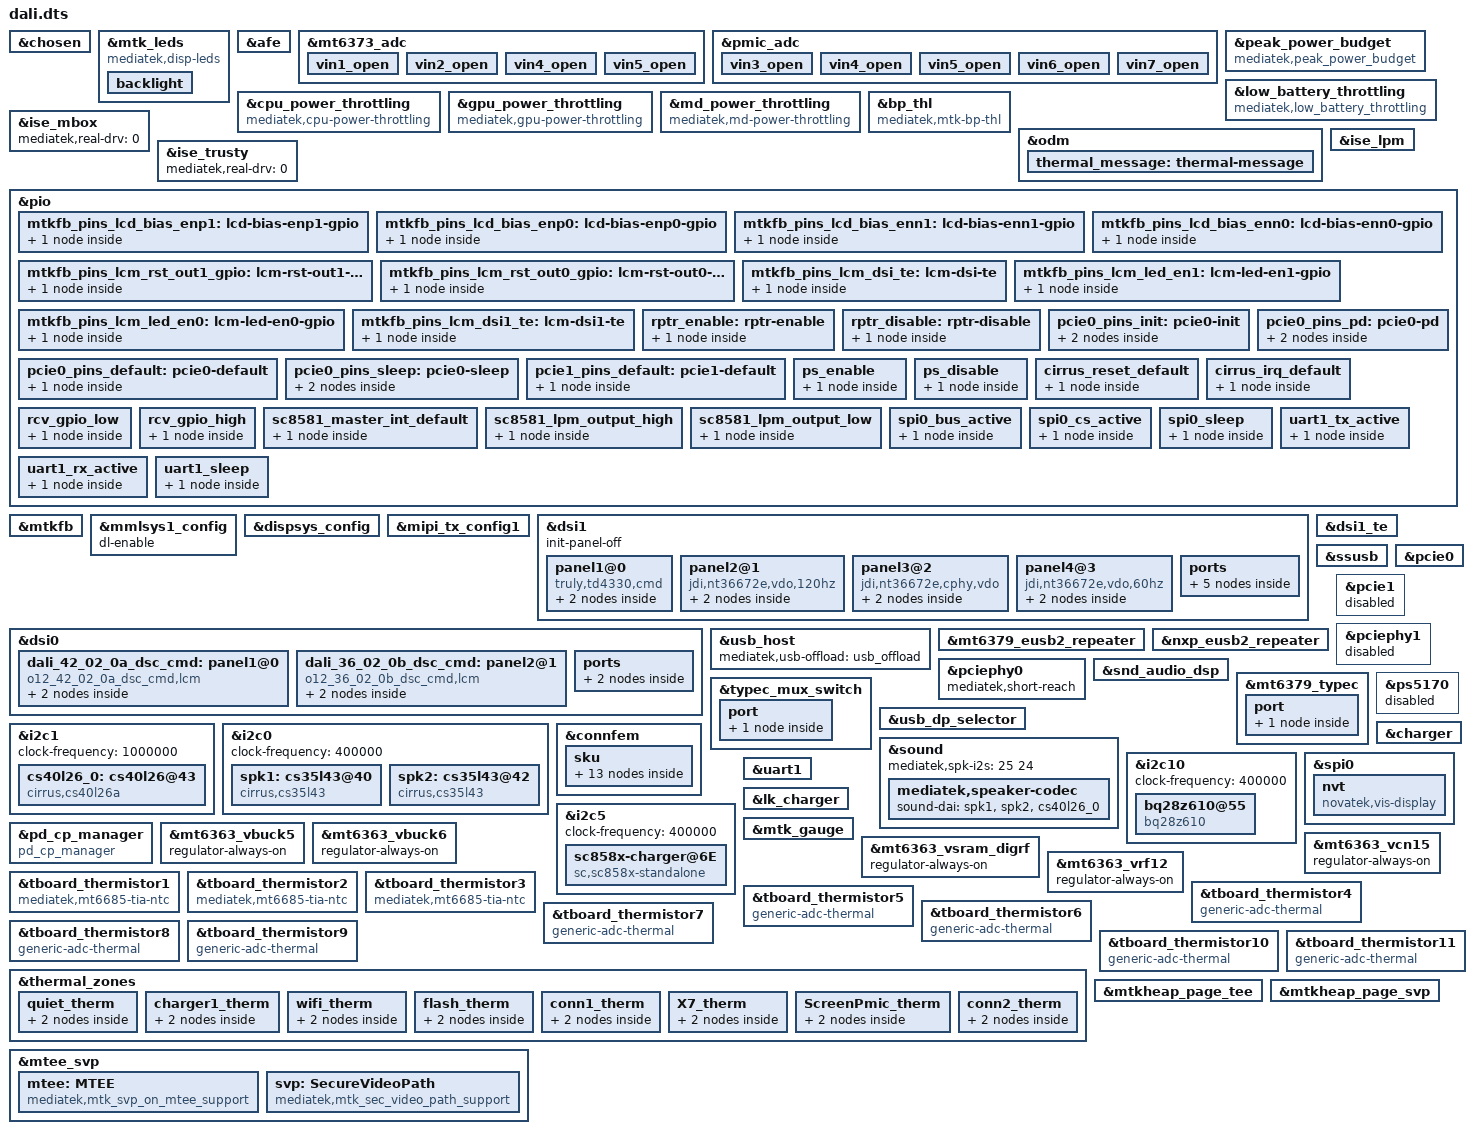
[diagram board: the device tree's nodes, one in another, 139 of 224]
// SPDX-License-Identifier: (GPL-2.0 OR MIT)
/*
 * Copyright (C) 2022 MediaTek Inc.
 */
/dts-v1/;
/plugin/;
#include <dt-bindings/interrupt-controller/arm-gic.h>
#include <dt-bindings/interrupt-controller/irq.h>
#include <dt-bindings/phy/phy.h>
#include <dt-bindings/pinctrl/mt6991-pinfunc.h>
#include <dt-bindings/power/mt6991-power.h>
#include <dt-bindings/gpio/gpio.h>
#include <dt-bindings/input/input.h>
#include <dt-bindings/iio/mt635x-auxadc.h>
#include <dt-bindings/thermal/thermal.h>
#include "mediatek/dali-mt6991-common.dtsi"
#include "mediatek/dali-sensor-common.dtsi"
#include "mediatek/xiaomi_dali_t1_chip.dtsi"


&chosen {
bootargs_ext = "cpufreq.default_governor=conservative \
		rcu_nocbs=0-7";
bootargs_ext_fac = "cpufreq.default_governor=conservative \
		rcu_nocbs=0-7";
};

&mtk_leds {
	compatible = "mediatek,disp-leds";

	backlight {
		max-brightness = <16383>;
		min-brightness = <1>;
		max-hw-brightness = <16383>;
		led_mode = <4>;
		default-state = "FifteenPercent";
	};
};

&afe {
	etdm-out-ch = <2 2 2 2 4 16 2>;
	etdm-in-ch = <2 2 2 2 4 16 16>;
	etdm-in-format = <0 0 0 0 4 0 0>; /*0: I2S; 1: LJ; 2: RJ; 3: EIAJ; 4: DSPA; 5: DSPB; 6: DSD */
	etdm-out-format = <0 0 0 0 4 0 0>;
	etdm-out-sync = <0 0 0 0 0 0 0>; /* 0: disable; 1: enable */
	etdm-in-sync = <1 0 0 0 1 1 1>; /* 0: disable; 1: enable */
	etdm-ip-mode = <0 0 0 0 0 0 0>; /* 0: One IP multi-channel 1: Multi-IP 2-channel */
};

&mt6373_adc {
	vin1_open {
		channel = <AUXADC_VIN1>;
		pures = <ADC_PURES_100K>;
	};
	vin2_open {
		channel = <AUXADC_VIN2>;
		pures = <ADC_PURES_100K>;
	};
	vin4_open {
		channel = <AUXADC_VIN4>;
		pures = <ADC_PURES_100K>;
	};
	vin5_open {
		channel = <AUXADC_VIN5>;
		pures = <ADC_PURES_100K>;
	};
};

&pmic_adc {
	vin3_open {
		channel = <AUXADC_VIN3>;
		pures = <ADC_PURES_100K>;
	};
	vin4_open {
		channel = <AUXADC_VIN4>;
		pures = <ADC_PURES_100K>;
	};
	vin5_open {
		channel = <AUXADC_VIN5>;
		pures = <ADC_PURES_100K>;
	};
	vin6_open {
		channel = <AUXADC_VIN6>;
		pures = <ADC_PURES_100K>;
	};
	vin7_open {
		channel = <AUXADC_VIN7>;
		pures = <ADC_PURES_100K>;
	};
};

&peak_power_budget {
	compatible = "mediatek,peak_power_budget";

	battery-circult-rdc = <15>;
	battery0-path-rac-t0 = <44>;
	battery0-path-rac-t1 = <44>;
	battery0-path-rac-t2 = <44>;
	battery0-path-rac-t3 = <44>;
	battery0-path-rac-t4 = <44>;
	battery0-path-rac-t5 = <44>;
	battery1-path-rac-t0 = <42>;
	battery1-path-rac-t1 = <42>;
	battery1-path-rac-t2 = <42>;
	battery1-path-rac-t3 = <42>;
	battery1-path-rac-t4 = <42>;
	battery1-path-rac-t5 = <42>;

	system-uvlo = <2450>;

	max-temperature-stage = <5>;
	temperature-threshold = <25 10 0 0xFFFFFFF6 0xFFFFFFEC>;

	soc-max-level = <4>;
	soc-hpt-ctrl-lv1 = <7>;
	soc-hpt-ctrl-lv2 = <0>;
	soc-hpt-ctrl-lv3 = <0>;
	soc-hpt-ctrl-lv4 = <0>;

	bat-ocv-table-num = <0>;
};

&low_battery_throttling {
		compatible = "mediatek,low_battery_throttling";
		lvsys-thd-enable = <1>;
		vbat-thd-enable = <1>;
		bat0-thd-volts-l = <
			3100 3000 2850
			3250 3150 3000
			3300 3200 3050
			3450 3350 3200
			3570 3470 3320>;
		bat0-thd-volts-h = <
			3200 3100 3000
			3350 3250 3150
			3400 3300 3200
			3550 3450 3350
			3670 3570 3470>;
		bat1-thd-volts-l = <
			3170 3070 2920
			3230 3130 2980
			3290 3190 3040
			3400 3300 3150
			3746 3646 3496>;
		bat1-thd-volts-h = <
			3270 3170 3070
			3330 3230 3130
			3390 3290 3190
			3500 3400 3300
			3846 3746 3646>;
		lvsys-thd-volt-l = <2850>;
		lvsys-thd-volt-h = <3000>;
		temperature-stage-threshold = <25 10 0 0xFFFFFFF6>;

		throttle-level = <0 1 2 3>,
				<0 1 2 3>,
				<0 1 2 3>,
				<0 1 2 3>,
				<0 1 2 3>;
};

&cpu_power_throttling{
	compatible = "mediatek,cpu-power-throttling";

	lbat-max-level = <3>;
	lbat-limit-freq-lv1 = < 1200000  1200000 1200000>;
	lbat-limit-freq-lv2 = < 1200000  1200000 1200000>;
	lbat-limit-freq-lv3 = < 330000  550000 670000>;

	oc-max-level = <2>;
	oc-limit-freq-lv1 = < 2147483647  2147483647 2147483647>;
	oc-limit-freq-lv2 = < 1200000  1700000 1900000>;

	soc-max-level = <4>;
	soc-core-active-lv1 = < 1 1 1 1 1 1 1 1 >;
	soc-core-active-lv2 = < 1 1 1 1 1 1 1 1 >;
	soc-core-active-lv3 = < 1 1 1 1 1 1 1 1 >;
	soc-core-active-lv4 = < 1 1 1 1 1 1 0 0 >;
	soc-limit-freq-lv1 = < 2147483647  2147483647 2147483647 >;
	soc-limit-freq-lv2 = < 2147483647  2147483647 2147483647 >;
	soc-limit-freq-lv3 = < 1200000 1200000 1200000>;
	soc-limit-freq-lv4 = < 1800000 900000 670000>;
};

&gpu_power_throttling{
	compatible = "mediatek,gpu-power-throttling";

	lbat-max-level = <3>;
	lbat-limit-freq-lv1 = <754000>;
	lbat-limit-freq-lv2 = <754000>;
	lbat-limit-freq-lv3 = <338000>;

	oc-max-level = <2>;
	oc-limit-freq-lv1 = <988000>;
	oc-limit-freq-lv2 = <572000>;

	soc-max-level = <4>;
	soc-limit-freq-lv1 = <2147483647>;
	soc-limit-freq-lv2 = <2147483647>;
	soc-limit-freq-lv3 = <754000>;
	soc-limit-freq-lv4 = <338000>;
};

&md_power_throttling {
		compatible = "mediatek,md-power-throttling";
		lbat-dedicate-volts = <3700 3400 3200 3000>;

		lbat-max-level = <3>;
		lbat-reduce-tx-lv1 = <0>;
		lbat-reduce-tx-lv2 = <2>;
		lbat-reduce-tx-lv3 = <2>;

		oc-max-level = <2>;
		oc-reduce-tx-lv1 = <0>;
		oc-reduce-tx-lv2 = <6>;

		soc-max-level = <0>;
};

&bp_thl{
	compatible = "mediatek,mtk-bp-thl";

	max-throttle-level = <4>;
	soc-throttle-level = <0 1 1 2 3>, //temperature stage 0
					<0 1 1 2 3>, //temperature stage 1
					<0 1 1 2 3>, //temperature stage 2
					<0 1 4 4 4>; //temperature stage 3

	soc-max-stage = <4>;
	soc-limit-threshold = <15 7 6 5>;

	temperature-max-stage = <3>;
	temperature-stage-threshold = <25 10 0>;

	md-soc-throttle-l = <20>;
	md-soc-throttle-h = <25>;
};

&odm {
	thermal_message: thermal-message {
		board-sensor = "VIRTUAL-SENSOR";
		board-sensor-trip-enable = <1>;
		trip-point-high = <41000>;
		trip-point-low = <40000>;
	};
};

&ise_mbox {
	mediatek,real-drv = <0>;
};

&ise_lpm {
	ise-wakelock = <0>;
	ise-lpm-freerun = <0>;
	ise-lpm-deinit-bypass = <0>;
};

&ise_trusty {
	mediatek,real-drv = <0>;
};



&pio {
	mtkfb_pins_lcd_bias_enp1: lcd-bias-enp1-gpio {
		pins-cmd-dat {
			pinmux = <PINMUX_GPIO103__FUNC_GPIO103>;
			slew-rate = <1>;
			output-high;
		};
	};

	mtkfb_pins_lcd_bias_enp0: lcd-bias-enp0-gpio {
		pins-cmd-dat {
			pinmux = <PINMUX_GPIO103__FUNC_GPIO103>;
			slew-rate = <1>;
			output-low;
		};
	};

	mtkfb_pins_lcd_bias_enn1: lcd-bias-enn1-gpio {
		pins-cmd-dat {
			pinmux = <PINMUX_GPIO103__FUNC_GPIO103>;
			slew-rate = <1>;
			output-high;
		};
	};

	mtkfb_pins_lcd_bias_enn0: lcd-bias-enn0-gpio {
		pins-cmd-dat {
			pinmux = <PINMUX_GPIO103__FUNC_GPIO103>;
			slew-rate = <1>;
			output-low;
		};
	};

	mtkfb_pins_lcm_rst_out1_gpio: lcm-rst-out1-gpio {
		pins-cmd-dat {
			pinmux = <PINMUX_GPIO90__FUNC_GPIO90>;
			slew-rate = <1>;
			output-high;
		};
	};

	mtkfb_pins_lcm_rst_out0_gpio: lcm-rst-out0-gpio {
		pins-cmd-dat {
			pinmux = <PINMUX_GPIO90__FUNC_GPIO90>;
			slew-rate = <1>;
			output-low;
		};
	};

	mtkfb_pins_lcm_dsi_te: lcm-dsi-te {
		pins-cmd-dat {
			pinmux = <PINMUX_GPIO89__FUNC_DSI_TE>;
		};
	};

	mtkfb_pins_lcm_led_en1: lcm-led-en1-gpio {
		pins-cmd-dat {
			pinmux = <PINMUX_GPIO174__FUNC_GPIO174>;
			slew-rate = <1>;
			output-high;
		};
	};

	mtkfb_pins_lcm_led_en0: lcm-led-en0-gpio {
		pins-cmd-dat {
			pinmux = <PINMUX_GPIO174__FUNC_GPIO174>;
			slew-rate = <1>;
			output-low;
		};
	};

	mtkfb_pins_lcm_dsi1_te: lcm-dsi1-te {
		pins-cmd-dat {
			pinmux = <PINMUX_GPIO6__FUNC_DSI1_TE>;
		};
	};
};

&mtkfb {
	pinctrl-names = "lcd_bias_enp1_gpio", "lcd_bias_enp0_gpio",
		"lcd_bias_enn1_gpio", "lcd_bias_enn0_gpio",
		"lcm_rst_out1_gpio", "lcm_rst_out0_gpio",
		"mode_te_te", "lcm_led_en1_gpio", "lcm_led_en0_gpio",
		"mode_te_te1";
	pinctrl-0 = <&mtkfb_pins_lcd_bias_enp1>;
	pinctrl-1 = <&mtkfb_pins_lcd_bias_enp0>;
	pinctrl-2 = <&mtkfb_pins_lcd_bias_enn1>;
	pinctrl-3 = <&mtkfb_pins_lcd_bias_enn0>;
	pinctrl-4 = <&mtkfb_pins_lcm_rst_out1_gpio>;
	pinctrl-5 = <&mtkfb_pins_lcm_rst_out0_gpio>;
	pinctrl-6 = <&mtkfb_pins_lcm_dsi_te>;
	pinctrl-7 = <&mtkfb_pins_lcm_led_en1>;
	pinctrl-8 = <&mtkfb_pins_lcm_led_en0>;
	pinctrl-9 = <&mtkfb_pins_lcm_dsi1_te>;

	status = "okay";
};

&mmlsys1_config {
	 dl-enable;
};

&dispsys_config {
	pinctrl-names = "mode_te_te", "mode_te_te1";
	pinctrl-0 = <&mtkfb_pins_lcm_dsi_te>;
	pinctrl-1 = <&mtkfb_pins_lcm_dsi1_te>;

	status = "okay";
	lk_mode_index = <2>;
//	enable-discrete-path = <1>;

	helper-value = <0>, /*MTK_DRM_OPT_STAGE*/
		<1>, /*MTK_DRM_OPT_USE_CMDQ*/
		<1>, /*MTK_DRM_OPT_USE_M4U*/
		<1>, /*MTK_DRM_OPT_MMQOS_SUPPORT*/
		<1>, /*MTK_DRM_OPT_MMDVFS_SUPPORT*/
		<0>, /*MTK_DRM_OPT_SODI_SUPPORT*/
		<1>, /*MTK_DRM_OPT_IDLE_MGR*/
		<0>, /*MTK_DRM_OPT_IDLEMGR_SWTCH_DECOUPLE*/
		<0>, /*MTK_DRM_OPT_IDLEMGR_BY_REPAINT*/
		<0>, /*MTK_DRM_OPT_IDLEMGR_ENTER_ULPS*/
		<0>, /*MTK_DRM_OPT_IDLEMGR_KEEP_LP11*/
		<0>, /*MTK_DRM_OPT_DYNAMIC_RDMA_GOLDEN_SETTING*/
		<1>, /*MTK_DRM_OPT_IDLEMGR_DISABLE_ROUTINE_IRQ*/
		<1>, /*MTK_DRM_OPT_IDLEMGR_ASYNC*/
		<0>, /*MTK_DRM_OPT_MET_LOG*/
		<1>, /*MTK_DRM_OPT_USE_PQ*/
		<1>, /*MTK_DRM_OPT_ESD_CHECK_RECOVERY*/
		<1>, /*MTK_DRM_OPT_ESD_CHECK_SWITCH*/
		<1>, /*MTK_DRM_OPT_PRESENT_FENCE*/
		<0>, /*MTK_DRM_OPT_RDMA_UNDERFLOW_AEE*/
		<1>, /*MTK_DRM_OPT_DSI_UNDERRUN_AEE*/
		<0>, /*MTK_DRM_OPT_ODDMR_UNDERRUN_AEE*/
		<1>, /*MTK_DRM_OPT_HRT*/
		<0>, /*MTK_DRM_OPT_HRT_MODE*/
		<0>, /*MTK_DRM_OPT_DELAYED_TRIGGER*/
		<0>, /*MTK_DRM_OPT_OVL_EXT_LAYER*/
		<0>, /*MTK_DRM_OPT_AOD*/
		<1>, /*MTK_DRM_OPT_RPO*/
		<0>, /*MTK_DRM_OPT_DUAL_PIPE*/
		<0>, /*MTK_DRM_OPT_DC_BY_HRT*/
		<1>, /*MTK_DRM_OPT_OVL_WCG*/
		<0>, /*MTK_DRM_OPT_OVL_SBCH*/
		<1>, /*MTK_DRM_OPT_COMMIT_NO_WAIT_VBLANK*/
		<0>, /*MTK_DRM_OPT_MET*/
		<0>, /*MTK_DRM_OPT_REG_PARSER_RAW_DUMP*/
		<0>, /*MTK_DRM_OPT_VP_PQ*/
		<0>, /*MTK_DRM_OPT_GAME_PQ*/
		<0>, /*MTK_DRM_OPT_MMPATH*/
		<0>, /*MTK_DRM_OPT_HBM*/
		<0>, /*MTK_DRM_OPT_VDS_PATH_SWITCH*/
		<0>, /*MTK_DRM_OPT_LAYER_REC*/
		<1>, /*MTK_DRM_OPT_CLEAR_LAYER*/
		<0>, /*MTK_DRM_OPT_LFR*/
		<0>, /*MTK_DRM_OPT_SF_PF*/
		<0>, /*MTK_DRM_OPT_DYN_MIPI_CHANGE*/
		<0>, /*MTK_DRM_OPT_PRIM_DUAL_PIPE*/
		<0>, /*MTK_DRM_OPT_MSYNC2_0*/
		<0>, /*MTK_DRM_OPT_MSYNC2_0_WAIT_EPT*/
		<1>, /*MTK_DRM_OPT_MML_PRIMARY*/
		<1>, /*MTK_DRM_OPT_MML_SUPPORT_CMD_MODE*/
		<1>, /*MTK_DRM_OPT_MML_PQ*/
		<1>, /*MTK_DRM_OPT_MML_IR*/
		<0>, /*MTK_DRM_OPT_DUAL_TE*/
		<0>, /*MTK_DRM_OPT_RES_SWITCH*/
		<0>, /*MTK_DRM_OPT_RES_SWITCH_ON_AP*/
		<0>, /*MTK_DRM_OPT_PREFETCH_TE*/
		<0>, /*MTK_DRM_OPT_VIDLE_APSRC_OFF*/
		<0>, /*MTK_DRM_OPT_VIDLE_DSI_PLL_OFF*/
		<0>, /*MTK_DRM_OPT_CHECK_TRIGGER_MERGE*/
		<0>, /*MTK_DRM_OPT_VIRTUAL_DISP*/
		<1>, /*MTK_DRM_OPT_OVL_BW_MONITOR*/
		<0>, /*MTK_DRM_OPT_GPU_CACHE*/
		<1>, /*MTK_DRM_OPT_SPHRT*/
		<0>, /*MTK_DRM_OPT_SDPA_OVL_SWITCH*/
		<1>, /*MTK_DRM_OPT_HRT_BY_LARB*/
		<0>, /*MTK_DRM_OPT_TILE_OVERHEAD*/
		<1>, /*MTK_DRM_OPT_VIDLE_TOP_EN*/
		<0>, /*MTK_DRM_OPT_VIDLE_MTCMOS_DT_EN*/
		<0>, /*MTK_DRM_OPT_VIDLE_MMINFRA_DT_EN*/
		<0>, /*MTK_DRM_OPT_VIDLE_DVFS_DT_EN*/
		<0>, /*MTK_DRM_OPT_VIDLE_QOS_DT_EN*/
		<0>, /*MTK_DRM_OPT_VIDLE_GCE_TS_EN*/
		<1>, /*MTK_DRM_OPT_VIDLE_FULL_SCENARIO*/
		<0>, /*MTK_DRM_OPT_DPC_PRE_TE_EN*/
		<1>, /*MTK_DRM_OPT_PARTIAL_UPDATE*/
		<0>, /*MTK_DRM_OPT_SLC_ALL_CACHE*/
		<1>, /*MTK_DRM_OPT_OVL_WCG_BY_COLOR_MODE*/
		<0>, /*"MTK_DRM_OPT_OVLSYS_CASCADE"*/
		<1>; /*MTK_DRM_OPT_LTPO_VM*/
};

&mipi_tx_config1 {
//	status = "okay";
};

&dsi1 {
//	status = "okay";
	#address-cells = <1>;
	#size-cells = <0>;
	init-panel-off;
	panel1@0 {
		compatible = "truly,td4330,cmd";
		reg = <0>;
		pm-enable-gpios = <&pio 215 0>;
		reset-gpios = <&pio 5 0>;
		swap-from-dts;
		lane-swap-setting = <1 2 0 3 4 2>;
		pn-swap-setting = <1 1 1 1 1 1>;
		gate-ic = <4831>;
		pinctrl-names = "default";
		port {
			panel1_in: endpoint {
				remote-endpoint = <&dsi1_out>;
			};
		};
	};
	panel2@1 {
		compatible = "jdi,nt36672e,vdo,120hz";
		reg = <1>;
		pm-enable-gpios = <&pio 215 0>;
		reset-gpios = <&pio 5 0>;
		gate-ic = <4831>;
		pinctrl-names = "default";
		port {
			panel2_in: endpoint {
				remote-endpoint = <&dsi1_out2>;
			};
		};
	};
	panel3@2 {
		compatible = "jdi,nt36672e,cphy,vdo";
		reg = <2>;
		pm-enable-gpios = <&pio 215 0>;
		reset-gpios = <&pio 5 0>;
		gate-ic = <4831>;
		pinctrl-names = "default";
		port {
			panel3_in: endpoint {
				remote-endpoint = <&dsi1_out3>;
			};
		};
	};
	panel4@3 {
		compatible = "jdi,nt36672e,vdo,60hz";
		reg = <3>;
		pm-enable-gpios = <&pio 215 0>;
		reset-gpios = <&pio 5 0>;
		gate-ic = <4831>;
		pinctrl-names = "default";
		port {
			panel4_in: endpoint {
				remote-endpoint = <&dsi1_out4>;
			};
		};
	};
	ports {
		port {
			dsi1_out: endpoint@0 {
				remote-endpoint = <&panel1_in>;
			};

			dsi1_out2: endpoint@1 {
				remote-endpoint = <&panel2_in>;
			};

			dsi1_out3: endpoint@2 {
				remote-endpoint = <&panel3_in>;
			};

			dsi1_out4: endpoint@3 {
				remote-endpoint = <&panel4_in>;
			};
		};
	};
};

&dsi1_te {
	interrupt-parent = <&pio>;
	interrupts = <6 1 6 1>;
	status = "okay";
};

&dsi0 {
	status = "okay";
	#address-cells = <1>;
	#size-cells = <0>;

	dali_42_02_0a_dsc_cmd: panel1@0 {
		compatible = "o12_42_02_0a_dsc_cmd,lcm";
		reg = <0>;
		reset-gpios = <&pio 90 0>;
		mi,esd-err-irq-gpio = <&pio 6 0x2002>;
		lane-swap-setting = <1 2 0 3 4 2>;
		pn-swap-setting = <1 1 1 1 1 1>;
		pinctrl-names = "default";
		vcn18io-supply = <&mt6373_vcn18io>;
		vibr-supply = <&mt6373_vibr>;
		//vbuck8-supply = <&mt6373_vbuck8>;
		dvdd-gpios = <&pio 92 0>;
		nt335_0p8-gpios = <&pio 26 0>;
		nt335_1p8-gpios = <&pio 181 0>;
		nt335_xtal1p8-gpios = <&pio 206 0>;
		port {
			panel_in1: endpoint {
				remote-endpoint = <&dsi_out>;
			};
		};
	};
	dali_36_02_0b_dsc_cmd: panel2@1 {
		compatible = "o12_36_02_0b_dsc_cmd,lcm";
		reg = <1>;
		reset-gpios = <&pio 90 0>;
		mi,esd-err-irq-gpio = <&pio 6 0x2002>;
		lane-swap-setting = <1 2 0 3 4 2>;
		pn-swap-setting = <1 1 1 1 1 1>;
		pinctrl-names = "default";
		vcn18io-supply = <&mt6373_vcn18io>;
		vibr-supply = <&mt6373_vibr>;
		//vbuck8-supply = <&mt6373_vbuck8>;
		dvdd-gpios = <&pio 92 0>;
		nt335_0p8-gpios = <&pio 26 0>;
		nt335_1p8-gpios = <&pio 181 0>;
		nt335_xtal1p8-gpios = <&pio 206 0>;
		port {
			panel_in2: endpoint {
				remote-endpoint = <&dsi_out>;
			};
		};
	};
	ports {
		port {
			dsi_out: endpoint {
				remote-endpoint = <&panel_in1>;
			};
		};
	};
};

&pio {
	rptr_enable: rptr-enable {
		pins-cmd-dat {
			pinmux = <PINMUX_GPIO72__FUNC_GPIO72>;
			output-high;
		};
	};

	rptr_disable: rptr-disable {
		pins-cmd-dat {
			pinmux = <PINMUX_GPIO72__FUNC_GPIO72>;
			output-low;
		};
	};
};

&ssusb {
	mediatek,force-vbus;
	mediatek,clk-mgr;
	mediatek,usb3-drd;
	mediatek,uds = <&usb_dp_selector 19>;
	mediatek,eusb2-cm-l1 = <0x474>;
	usb-role-switch;
	status = "okay";
};

&usb_host {
	mediatek,usb-offload = <&usb_offload>;
	status = "okay";
};

&mt6379_eusb2_repeater {
	mediatek,discth = <0xf>;
	mediatek,equalization = <0x4>;
	mediatek,intr-ofs = "2";
	mediatek,pre-emphasis = <0x5>;
	mediatek,rx-sqth = <0x0>;
	mediatek,term-ofs = "4";
	mediatek,vrt-sel = <0x2>;

	mediatek,host-discth = <0xd>;
	mediatek,host-equalization = <0x4>;
	mediatek,host-intr-ofs = "3";
	mediatek,host-pre-emphasis = <0x2>;
	mediatek,host-rx-sqth = <0x0>;
	mediatek,host-term-ofs = "-2";
	mediatek,host-vrt-sel = <0x2>;
	status = "okay";
};

&nxp_eusb2_repeater {
	pinctrl-names = "enable", "disable";
	pinctrl-0 = <&rptr_enable>;
	pinctrl-1 = <&rptr_disable>;
	status = "okay";
};

&pcie0 {
	pinctrl-names = "init", "default", "sleep", "pd";
	pinctrl-0 = <&pcie0_pins_init>;
	pinctrl-1 = <&pcie0_pins_default>;
	pinctrl-2 = <&pcie0_pins_sleep>;
	pinctrl-3 = <&pcie0_pins_pd>;
	max-link-speed = <4>;
	status = "okay";
};

&pcie1 {
	pinctrl-names = "default";
	pinctrl-0 = <&pcie1_pins_default>;
	max-link-speed = <4>;
	status = "disabled";
};

&pciephy0 {
	mediatek,short-reach;
	status = "okay";
};

&pciephy1 {
	status = "disabled";
};

/* PCIe pinmux start */
/* skyhawk use waken to control DFD_EN, PCIe0 don't need to control it */
&pio {
	pcie0_pins_init: pcie0-init {
		pins-cmd-dat {
			pinmux = <PINMUX_GPIO241__FUNC_GPIO241>;
			output-low;
		};

		pins-cmd-dat1 {
			pinmux = <PINMUX_GPIO243__FUNC_GPIO243>;
			bias-pull-up;
			input-enable;
		};
	};

	pcie0_pins_default: pcie0-default {
		pins-cmd-dat {
			pinmux = <PINMUX_GPIO241__FUNC_PCIE_PERSTN>,
				 <PINMUX_GPIO243__FUNC_PCIE_CLKREQN>;
			bias-pull-up;
		};
	};

	pcie0_pins_sleep: pcie0-sleep {
		pins-cmd-dat {
			pinmux = <PINMUX_GPIO241__FUNC_GPIO241>;
			output-low;
		};

		pins-cmd-dat1 {
			pinmux = <PINMUX_GPIO243__FUNC_GPIO243>;
			bias-pull-up;
			input-enable;
		};
	};

	pcie0_pins_pd: pcie0-pd {
		pins-cmd-dat {
			pinmux = <PINMUX_GPIO241__FUNC_GPIO241>;
			output-low;
		};

		pins-cmd-dat1 {
			pinmux = <PINMUX_GPIO243__FUNC_GPIO243>;
			bias-pull-down;
			input-enable;
		};
	};

	pcie1_pins_default: pcie1-default {
		pins-cmd-dat {
			pinmux = <PINMUX_GPIO145__FUNC_PCIE_WAKEN_1P>,
				 <PINMUX_GPIO146__FUNC_PCIE_PERSTN_1P>,
				 <PINMUX_GPIO147__FUNC_PCIE_CLKREQN_1P>;
			bias-pull-up = <MTK_PUPD_SET_R1R0_01>;
		};
	};
};
/* PCIe pinmux end */

&snd_audio_dsp {
	swdsp-smartpa-process-enable = <0x0>;
	mtk-dsp-call-final = <0x0>;
};

#if 0
/* no need set here, 6686 will control elna automatically */
/* GPS GPIO standardization start */
&pio {
	gps_pins_default: gps_default {
	};
	gps_l1_lna_pins_ol: gps-l1-lna0 {
		pins-cmd-dat {
			pinmux = <PINMUX_GPIO12__FUNC_GPIO12>;
			output-low;
		};
	};
	gps_l1_lna_pins_dsp_ctrl: gps-l1-lna1 {
		pins-cmd-dat {
			pinmux = <PINMUX_GPIO12__FUNC_GPS_L1_ELNA_EN>;
		};
	};
	gps_l1_lna_pins_oh: gps-l1-lna2 {
		pins-cmd-dat {
			pinmux = <PINMUX_GPIO12__FUNC_GPIO12>;
			output-high;
		};
	};
	gps_l5_lna_pins_ol: gps-l5-lna0 {
		pins-cmd-dat {
			pinmux = <PINMUX_GPIO13__FUNC_GPIO13>;
			output-low;
		};
	};
	gps_l5_lna_pins_dsp_ctrl: gps-l5-lna1 {
		pins-cmd-dat {
			pinmux = <PINMUX_GPIO13__FUNC_GPS_L5_ELNA_EN>;
		};
	};
	gps_l5_lna_pins_oh: gps-l5-lna2 {
		pins-cmd-dat {
			pinmux = <PINMUX_GPIO13__FUNC_GPIO13>;
			output-high;
		};
	};
};
&gps {
	pinctrl-names = "default",
		"gps_l1_lna_disable",
		"gps_l1_lna_dsp_ctrl",
		"gps_l1_lna_enable",
		"gps_l5_lna_disable",
		"gps_l5_lna_dsp_ctrl",
		"gps_l5_lna_enable";
	pinctrl-0 = <&gps_pins_default>;
	pinctrl-1 = <&gps_l1_lna_pins_ol>;
	pinctrl-2 = <&gps_l1_lna_pins_dsp_ctrl>;
	pinctrl-3 = <&gps_l1_lna_pins_oh>;
	pinctrl-4 = <&gps_l5_lna_pins_ol>;
	pinctrl-5 = <&gps_l5_lna_pins_dsp_ctrl>;
	pinctrl-6 = <&gps_l5_lna_pins_oh>;
	status = "okay";
};
/* GPS GPIO standardization end */
#endif

/* usb typec mux start */
&pio {

	ps_enable: ps_enable {
		pins-cmd-dat {
			pinmux = <PINMUX_GPIO207__FUNC_GPIO207>;
			output-high;
		};
	};

	ps_disable: ps_disable {
		pins-cmd-dat {
			pinmux = <PINMUX_GPIO207__FUNC_GPIO207>;
			output-low;
		};
	};

};

&mt6379_typec {
	tcpc,en_floatgnd;
	/* 0:16x, 1:128x, 2:512x, 3:1024x */
	wd,wd0_tsleep = <1>;
	/* 0:400us, 1:1ms, 2:2ms, 3:4ms, 4:10ms, 5:40ms, 6:100ms, 7:400ms */
	wd,wd0_tdet = <3>;
	/* example wd0_tsleep = 512x, wd0_tdet = 4ms, wd0 polling time = 512*4ms */

	port {
		tcpc_typec_usb: endpoint {
			remote-endpoint = <&ssusb_mux>;
		};
	};
};

&typec_mux_switch {
	orientation-switch;
	mode-switch;
	accessory;
	port {
		ssusb_mux: endpoint {
			remote-endpoint = <&tcpc_typec_usb>;
		};
	};
};

&ps5170 {
	pinctrl-names = "enable", "disable";
	pinctrl-0 = <&ps_enable>;
	pinctrl-1 = <&ps_disable>;
	status = "disabled";
};

&usb_dp_selector {
	status = "okay";
};
/* usb typec mux end */

&pio {
	cirrus_reset_default: cirrus_reset_default {
        		pins-cmd-dat {
                        	pinmux = <PINMUX_GPIO42__FUNC_GPIO42>;
				bias-disable;
                                output-low;
                        };
		};
	cirrus_irq_default: cirrus_irq_default {
			pins-cmd-dat {
                        	pinmux = <PINMUX_GPIO5__FUNC_GPIO5>;
				input-enable;
                        };
		};
};

&i2c1 {
	clock-frequency = <1000000>;
	status = "ok";
	/* CS Haptic */
	cs40l26_0: cs40l26@43 {
                status = "ok";
                compatible = "cirrus,cs40l26a";
                #sound-dai-cells = <0>;
                reg = <0x43>;
                interrupt-parent = <&pio>;
                interrupts = <5 IRQ_TYPE_LEVEL_LOW>;
                reset-gpios = <&pio 42 1>;
                pinctrl-names = "default";
                pinctrl-0 = <&cirrus_reset_default &cirrus_irq_default>;

                cirrus,dbc-enable;
                cirrus,dbc-env-rel-coef = <8000000>;
                cirrus,dbc-fall-headroom = <7000000>;
                cirrus,dbc-rise-headroom = <6000000>;
                cirrus,dbc-tx-lvl-hold-off-ms = <50>;
                cirrus,dbc-tx-lvl-thresh-fs = <900>;
                cirrus,pm-active-timeout-ms = <200>;
                cirrus,pm-stdby-timeout-ms = <500>;
                cirrus,bst-ipk-microamp = <4000000>;

                cirrus,vbbr-enable;
                cirrus,vbbr-thld-uv = <656260>;
                cirrus,vbbr-max-att-db = <6>;
                cirrus,vbbr-atk-step = <1>;
                cirrus,vbbr-atk-rate = <1>;
                cirrus,vbbr-wait = <1>;
                cirrus,vbbr-rel-rate = <2>;

                cirrus,vpbr-enable;
                cirrus,vpbr-thld-uv = <2781500>;
                cirrus,vpbr-max-att-db = <6>;
                cirrus,vpbr-atk-step = <1>;
                cirrus,vpbr-atk-rate = <1>;
                cirrus,vpbr-wait = <1>;
                cirrus,vpbr-rel-rate = <2>;

                cirrus,f0-default = <(130 << 14)>;
        };
	/* CS Haptic */
};

/* cs35l43 rcv/spk switch */
&pio {
 	rcv_gpio_low: rcv_gpio_low {
 		pins_cmd_dat {
 			pinmux = <PINMUX_GPIO210__FUNC_GPIO210>;
 			drive-strength = <2>;
 			bias-pull-up;
 			output-high;
 		};
 	};
 	rcv_gpio_high: rcv_gpio_high {
 		pins_cmd_dat {
 			pinmux = <PINMUX_GPIO210__FUNC_GPIO210>;
 			drive-strength = <2>;
 			bias-pull-up;
 			output-high;
 		};
 	};
};
/* cs35l43 rcv/spk switch */

&i2c0 {
	/*
	spk1: speaker_amp@5c {
		compatible = "richtek,rt5512";
		#sound-dai-cells = <0>;
		reg = <0x5c>;
		status = "okay";
		sound-name-prefix = "Left";
	};

	spk2: speaker_amp@5d {
		compatible = "richtek,rt5512";
		#sound-dai-cells = <0>;
		reg = <0x5d>;
		status = "okay";
		sound-name-prefix = "Right";
	}; 
	*/
	clock-frequency = <400000>;
	spk1: cs35l43@40 {
 		status = "ok";
 		compatible = "cirrus,cs35l43";
		#sound-dai-cells = <0>;
		reg = <0x40>;
 		reset-gpios = <&pio 174 0>;
 		interrupt-parent = <&pio>;
 		interrupts = <10 IRQ_TYPE_LEVEL_LOW>;
		irq-gpio = <&pio 10 0>;
 		cirrus,bst-ipk-ma = <4500>;
 		cirrus,asp-sdout-hiz = <3>;
 		cirrus,gpio2-src-sel = <4>;
 		sound-name-prefix = "B";
 		cirrus,i2c-addr = <40>;
 		cirrus,low-pwr-mode-standby = <1>;
 		cirrus,vpbr-enable = <1>;
 		cirrus,vpbr-rel-rate = <7>;
 		cirrus,vpbr-wait = <2>;
 		cirrus,vpbr-atk-rate = <0>;
 		cirrus,vpbr-atk-vol = <2>;
 		cirrus,vpbr-max-att = <1>;
 		cirrus,vpbr-thld = <0x17>;
 	};

 	spk2: cs35l43@42 {
 		status = "ok";
 		compatible = "cirrus,cs35l43";
		#sound-dai-cells = <0>;
		reg = <0x42>;
 		reset-gpios = <&pio 91 0>;
 		interrupt-parent = <&pio>;
 		interrupts = <39 IRQ_TYPE_LEVEL_LOW>;
		irq-gpio = <&pio 39 0>;
		pinctrl-names = "rcv_gpio_high", "rcv_gpio_low";
		pinctrl-0 = <&rcv_gpio_high>;
		pinctrl-1 = <&rcv_gpio_low>;
 		cirrus,bst-ipk-ma = <4500>;
 		cirrus,asp-sdout-hiz = <3>;
 		cirrus,gpio2-src-sel = <4>;
 		sound-name-prefix = "T";
 		cirrus,i2c-addr = <42>;
 		cirrus,low-pwr-mode-standby = <1>;
 		cirrus,vpbr-enable = <1>;
 		cirrus,vpbr-rel-rate = <7>;
 		cirrus,vpbr-wait = <2>;
 		cirrus,vpbr-atk-rate = <0>;
 		cirrus,vpbr-atk-vol = <2>;
 		cirrus,vpbr-max-att = <1>;
 		cirrus,vpbr-thld = <0x17>;
 	};
};

&sound {
	mediatek,spk-i2s = <25 24>;
	mediatek,speaker-codec {
		sound-dai = <&spk1>, <&spk2>, <&cs40l26_0>;
	};
};

#if 0
&pdc {
	pd_vbus_upper_bound = <12000000>;
};
#endif

&connfem {
	sku {
		hw-names =
			"qm42655_qm45655_2g2a",	/* [0] QM42655/QM45655, 2G+2A */
			"vc536421_vc576821";	/* [1] VC536421/VC576821, 2G+2A*/
		hwid {
			gpio = <&pio 43 0x0>;      /* bit 0 */
		};

		/***************************************************************
		 * [HW][0] QM42655/QM45655, 2G+2A
		 **************************************************************/
		hw-0 {
			using-fems =
				<&qm42655>,
				<&qm45655>;

			layout-flag = <0x00000000>;
			layout =
				<&g_wf0_bt0_qm42655>,
				<&g_wf1_bt1_qm42655>,
				<&a_wf0_qm45655>,
				<&a_wf1_qm45655>;

			common {
				flags {
					fe-ant-cnt = [85];
					fe-conn-dpdt-sp3t = [80];
					fe-conn-spdt = [80];
					fe-bt-wf-usage = [80];
					fe-conn-spdt-2 = [80];
				};
			};

			wifi {
				using-states =
					<&qm42655_rxl>,
					<&qm45655_rxh>;
			};

			bt {
				flags {
					efem-mode = [03]; /* 3:epa_elna, 2:epa, 1:elna, 0:bypass */
					rx-mode = [24]; /* 0x24: G-band RxL */
				};
			};
		};

		/***************************************************************
		 * [HW][1] VC536421/VC576821, 2G+2A
		 **************************************************************/
		hw-1 {
			using-fems =
				<&vc536421>,
				<&vc576821>;

			layout-flag = <0x00000000>;
			layout =
				<&g_wf0_bt0_vc536421>,
				<&g_wf1_bt1_vc536421>,
				<&a_wf0_vc576821>,
				<&a_wf1_vc576821>;

			common {
				flags {
					fe-ant-cnt = [85];
					fe-conn-dpdt-sp3t = [80];
					fe-conn-spdt = [80];
					fe-bt-wf-usage = [80];
					fe-conn-spdt-2 = [80];
				};
			};

			wifi {
				using-states =
					<&vc536421_rxl>,
					<&vc576821_rxh>;
			};

			bt {
				flags {
					efem-mode = [03]; /* 3:epa_elna, 2:epa, 1:elna, 0:bypass */
					rx-mode = [24]; /* 0x24: G-band RxL */
				};
			};
		};
	};
};

/* charger start */
&pio {
	sc8581_master_int_default: sc8581_master_int_default {
		pins-cmd-dat {
			pinmux = <PINMUX_GPIO76__FUNC_GPIO76>;
			input-enable;
		};
	};

	sc8581_lpm_output_high: sc8581_lpm_output_high {
		pins-cmd-dat {
			pinmux = <PINMUX_GPIO74__FUNC_GPIO74>;
			slew-rate = <1>;
			output-high;
		};
	};

	sc8581_lpm_output_low: sc8581_lpm_output_low {
		pins-cmd-dat {
			pinmux = <PINMUX_GPIO74__FUNC_GPIO74>;
			slew-rate = <1>;
			output-low;
		};
	};
};

&i2c10 {
	clock-frequency = <400000>;
	status = "okay";
	bq28z610@55 {
		compatible = "bq28z610";
		reg = <0x55>;
		max_chg_power_120w;
		enable_shutdown_delay;
		normal_shutdown_vbat_1s = <3400>;
		critical_shutdown_vbat_1s = <3340>;
		report_full_rsoc_1s = <9500>;
		soc_gap_1s = <2>;
//		slave_connect_gpio = <&pio 75 0x1>;
		soc_decimal_rate = <
			0  38
			10 35
			20 33
			30 33
			40 33
			50 33
			60 33
			70 30
			80 25
			90 20
			95 10 >;
	};
};

&i2c5 {
	clock-frequency = <400000>;
	status = "okay";
	sc858x-charger@6E{
		compatible = "sc,sc858x-standalone";
		reg = <0x6E>;
		sc,sc858x,irq-gpio = <&pio 27 IRQ_TYPE_EDGE_FALLING>;

		sc,sc858x,bat-ovp-disable = <0>;
		sc,sc858x,bat-ovp-threshold = <11>;/*4450 + val * 25*/
		sc,sc858x,usb-ovp-threshold = <11>;/*11000 + val * 1000*/
		sc,sc858x,wpc-ovp-threshold = <11>;/*11000 + val * 1000*/
		sc,sc858x,bus-ovp-threshold = <9>;/*15000 + val * 800*/
		sc,sc858x,out-ovp-threshold = <1>;/*4800 + val * 200*/
		sc,sc858x,bus-ocp-disable = <0>;
		sc,sc858x,bus-ocp-threshold = <15>;/*2500 + val * 125*/
		sc,sc858x,bus-ucp-fall-dg = <1>;/*0:8us 1:5ms 2:20ms 3:50ms*/
		sc,sc858x,pmid2out-ovp-threshold = <2>;/*200 + val * 100*/
		sc,sc858x,pmid2out-uvp-threshold = <7>;/*100 + val * 50*/
		sc,sc858x,fsw-set = <7>;/*180 + val * 60*/
		sc,sc858x,acdrv-hi-en = <1>;/*0:5V, 1:9V*/
		sc,sc858x,ss-timeout = <5>;/*0:dis 3:320ms 4:1.28s 5:5.12s 6:20.48s 7:81.92s*/
		sc,sc858x,wd-timeout = <0>;/*0:dis 1:0.2s 2:0.5s 3:1s 4:5s 5:30s*/
		sc,sc858x,mode = <1>;/*0:(4:1 chg) 1:(2:1 chg) 2:(1:1 chg) 4:(1:4 con) 5:(1:2 con) 6:(1:1 con)*/
		sc,sc858x,tsbat-flt-disable = <1>;
		sc,sc858x,tshut-disable = <1>;
		sc,sc858x,wpc-ovp-disable = <0>;
		sc,sc858x,usb-ovp-disable = <0>;
		sc,sc858x,bus-ovp-disable = <0>;
		sc,sc858x,out-ovp-disable = <0>;
		sc,sc858x,sense-r-mohm = <1>;/*0:1m  1:2m*/
		mt6375_ovp_en_gpio = <&pio 93 0x0>;
	};
};

&charger {
		max_charger_voltage = <12000000>;
		/* charging current */
		usb_charger_current = <500000>;
		ac_charger_current = <1600000>;
		ac_charger_input_current = <1600000>;
		charging_host_charger_current = <900000>;
		step_fallback_hyst = <125>;
		step_forward_hyst = <0>;
		jeita_fallback_hyst = <10>;
		jeita_forward_hyst = <10>;
		mt6368_moscon1_control;
		en_floatgnd;
		rust_support;
		smart_snschg_v2_support;
		pd2_input_current = <1700000>;
		min_charger_voltage_1 = <4600000>;
		min_charger_voltage_2 = <4600000>;
		sbu_uart_en = <&pio 24 0x0>;
		ffc_low_tbat = <180>;
		ffc_medium_tbat = <230>;
		ffc_warm_tbat = <350>;
		ffc_little_high_tbat = <400>;
		ffc_high_tbat = <480>;
		ffc_high_soc = <95>;
		adapter_power = <100>;
		io-channels = <&pmic_adc AUXADC_VIN4>;
		io-channel-names = "slave_connector_auxadc";

		/* CN battery paremeter */
		fv = <4520>;
		fv_normal = <4500>;
		fv_normal_warm = <4490>;
		fv_normal_high = <4480>;
		fv_ffc = <4580>;
		iterm = <401>;
		iterm_warm = <401>;
		jeita_fcc_cfg = <(-100)	30	4150	729	583
				31	80	4150	1358	994
				81	130	4150	2087	1358
				131	180	4150	8748	7290
				181	470	4200	17600	17600
				471	600	4100	3645	3645>;
		jeita_fv_cfg = <(-100)	30	4520
				31	80	4520
				81	130	4520
				131	180	4520
				181	470	4570
				471	600	4100>;

		/* ATL START */
		iterm_ffc_1_cycle_atl = <1282>;
		iterm_ffc_little_warm_1_cycle_atl = <1684>;
		iterm_ffc_warm_1_cycle_atl = <2480>;
		iterm_ffc_hot_1_cycle_atl = <3368>;

		/* ATL 12-23C cycle step */
		/* 1-50cls */
		step_chg_cfg_1_cycle_atl = <3000	4250	12400
					4251	4500	10935
					4501	4570	8748>;

		/* 50-100cls */
		step_chg_cfg_50_cycle_atl = <3000	4220	12400
					4221	4480	10935
					4481	4570	8748>;

		/* 100-150cls */
		step_chg_cfg_100_cycle_atl = <3000	4220	12400
					4221	4460	10935
					4461	4550	8748>;

		/* 150-300cls */
		step_chg_cfg_150_cycle_atl = <3000	4220	12400
					4221	4440	10935
					4441	4550	8748>;

		/* 300-800cls */
		step_chg_cfg_300_cycle_atl = <3000	4220	12400
					4221	4420	10935
					4421	4540	8748>;

		/* >800cls */
		step_chg_cfg_800_cycle_atl = <3000	4220	12400
					4221	4420	10935
					4421	4520	8748>;

		/* ATL 23-48C cycle step */
		/* 1-50cls */
		step_chg_cfg_warm_1_cycle_atl = <3000	4220	17400
						4221	4320	12400
						4321	4500	10940
						4501	4570	8750>;

		/* 50-100cls */
		step_chg_cfg_warm_50_cycle_atl = <3000	4190	17400
						4191	4300	11780
						4301	4480	10390
						4481	4570	8310>;

		/* 100-150cls */
		step_chg_cfg_warm_100_cycle_atl = <3000	4190	17400
						4191	4280	11160
						4281	4460	9840
						4461	4550	7870>;

		/* 150-300cls */
		step_chg_cfg_warm_150_cycle_atl = <3000	4190	17400
						4191	4260	10540
						4261	4400	9290
						4401	4550	7440>;

		/* 300-800cls */
		step_chg_cfg_warm_300_cycle_atl = <3000	4190	17400
						4191	4240	9920
						4241	4420	8750
						4421	4540	7000>;

		/* >800cls */
		step_chg_cfg_warm_800_cycle_atl = <3000	4190	17400
						4191	4240	9920
						4241	4420	8750
						4421	4520	7000>;
		/* ATL END */

		/* LWN START */
		iterm_ffc_1_cycle_lwn = <1443>;
		iterm_ffc_little_warm_1_cycle_lwn = <1844>;
		iterm_ffc_warm_1_cycle_lwn = <2646>;
		iterm_ffc_hot_1_cycle_lwn = <3448>;

		/* LWN 12-23C cycle step */
		/* 1-50cls */
		step_chg_cfg_1_cycle_lwn = <3000	4250	12400
					4251	4500	10935
					4501	4570	8748>;

		/* 50-100cls */
		step_chg_cfg_50_cycle_lwn = <3000	4220	12400
					4221	4480	10935
					4481	4570	8748>;

		/* 100-150cls */
		step_chg_cfg_100_cycle_lwn = <3000	4220	12400
					4221	4460	10935
					4461	4550	8748>;

		/* 150-300cls */
		step_chg_cfg_150_cycle_lwn = <3000	4220	12400
					4221	4440	10935
					4441	4550	8748>;

		/* 300-800cls */
		step_chg_cfg_300_cycle_lwn = <3000	4220	12400
					4221	4420	10935
					4421	4540	8748>;

		/* >800cls */
		step_chg_cfg_800_cycle_lwn = <3000	4220	12400
					4221	4420	10935
					4421	4520	8748>;

		/* LWN 23-48C cycle step */
		/* 1-50cls */
		step_chg_cfg_warm_1_cycle_lwn = <3000	4150	17400
						4151	4320	12400
						4321	4500	10940
						4501	4570	8750>;

		/* 50-100cls */
		step_chg_cfg_warm_50_cycle_lwn = <3000	4120	17400
						4121	4300	11780
						4301	4480	10390
						4481	4570	8310>;

		/* 100-150cls */
		step_chg_cfg_warm_100_cycle_lwn = <3000	4120	17400
						4121	4280	11160
						4281	4460	9840
						4461	4550	7870>;

		/* 150-300cls */
		step_chg_cfg_warm_150_cycle_lwn = <3000	4120	17400
						4121	4260	10540
						4261	4400	9290
						4401	4550	7440>;

		/* 300-800cls */
		step_chg_cfg_warm_300_cycle_lwn = <3000	4120	17400
						4121	4240	9920
						4241	4420	8750
						4421	4540	7000>;

		/* >800cls */
		step_chg_cfg_warm_800_cycle_lwn = <3000	4120	17400
						4121	4240	9920
						4241	4420	8750
						4421	4520	7000>;
		/* LWN END */

		thermal_limit_dcp = <1900 1900 1900 1900 1900 1900 1900 1900 1900 1900 1900 1900 1500 1400 1200 1000>;
		thermal_limit_qc2 = <2500 2500 2500 2500 2500 2500 2500 2500 2500 2500 2500 2000 1500 1500 1000 500>;
		thermal_limit_qc3_18w = <2500 2500 2500 2500 2500 2500 2400 2300 2200 2100 1500 1000 800 700 600 500>;
		thermal_limit_qc3_27w = <2500 2500 2500 2500 2500 2500 2400 2300 2200 2100 1500 1000 800 700 600 500>;
		thermal_limit_qc35 = <2500 2500 2500 2500 2500 2500 2400 2300 2200 2100 1500 1000 800 700 600 500>;
		thermal_limit_pd = <17600 13500 11000 9000 8000 7000 6000 5000 4500 3500 3000 2500 2000 1500 1000 500>;

		smart_bypass_support;
		smart_bypass_entry_soc = <20>;
		smart_bypass_exit_soc = <90>;
		smart_bypass_fallback_hyst = <5>; // board_temp(0.1 degree) hyst
		smart_bypass_forward_hyst = <5>;
		smart_bypass_high_lmt_cfg = <(-100)	250	3000
				251	280	2500
				281	300	2000
				301	330	1600
				331	370	1200
				371	800	900>;
		smart_bypass_med_lmt_cfg = <(-100)	150	17600
				151	200	17600
				201	250	17600
				251	300	8000
				301	370	5000
				371	800	2000>;
		smart_bypass_low_lmt_cfg = <(-100)	150	17600
				151	200	17600
				201	250	17600
				251	300	17600
				301	370	17600
				371	800	17600>;
};

/* nvt device tree node */
&pio {
	spi0_bus_active: spi0_bus_active {
		pins_cmd_dat {
			pinmux = <PINMUX_GPIO223__FUNC_SPI0_MI>, <PINMUX_GPIO222__FUNC_SPI0_MO>,
			<PINMUX_GPIO220__FUNC_SPI0_CLK>;
			slew-rate = <0>;
			drive-strength=<2>;
			bias-pull-down;
		};
	};

	spi0_cs_active: spi0_cs_active {
		pins_cmd_dat {
			pinmux = <PINMUX_GPIO221__FUNC_SPI0_CSB>;
			slew-rate = <0>;
			drive-strength=<2>;
			bias-pull-up;
		};
	};

	spi0_sleep: spi0_sleep {
		pins_cmd_dat {
			pinmux = <PINMUX_GPIO220__FUNC_GPIO220>, <PINMUX_GPIO221__FUNC_GPIO221>,
			<PINMUX_GPIO222__FUNC_GPIO222>, <PINMUX_GPIO223__FUNC_GPIO223>;
			slew-rate = <0>;
			bias-pull-down;
			input-enable;
		};
	};

	uart1_tx_active: uart1_tx_active {
		pins_cmd_dat {
			pinmux = <PINMUX_GPIO162__FUNC_UTXD1>;
			slew-rate = <0>;
			bias-disable;
		};
	};

	uart1_rx_active: uart1_rx_active {
		pins_cmd_dat {
			pinmux = <PINMUX_GPIO163__FUNC_URXD1>;
			slew-rate = <0>;
			bias-disable;
		};
	};

	uart1_sleep: uart1_sleep {
		pins_cmd_dat {
			pinmux = <PINMUX_GPIO162__FUNC_GPIO162>, <PINMUX_GPIO163__FUNC_GPIO163>;
			slew_rate = <0>;
			bias-pull-down;
			input-anable;
		};
	};
};

/* NVT ASIC Start */
&spi0 {
	status = "okay";
	dma-mode; /*enable spi dma mode */
	mediatek,pad-select = <0>;

	nvt {
		compatible = "novatek,vis-display";
		reg = <0x0>;
		status = "okay";
		spi-max-frequency = <26000000>;
		nvt,always08 = <&pio 26 0>;
		nvt,vsel08 = <&pio 207 0>;
		nvt,always18 = <&pio 181 0>;
		/*nvt,always12 = <&pio 9 0>;*/
		nvt,resetN = <&pio 186 0>;
		/*
		nvt,nonalways08 = <&pio 15 0>;
		nvt,nonalways18 = <&pio 17 0>;
		*/
		nvt,abnormal = <&pio 31 0>;
		nvt,ready = <&pio 193 0>;
		nvt,xtalEN = <&pio 206 0>;
		/*nvt,clock = <&pio 163 0>;*/
		pinctrl-names = "default", "sleep";
		pinctrl-0 = <&spi0_bus_active &spi0_cs_active &uart1_tx_active &uart1_rx_active>;
		pinctrl-1 = <&spi0_sleep &uart1_sleep>;
	};
};

&uart1 {
	status = "okay";
};
/* NVT ASIC End */



&lk_charger {
		/* charging current */
		usb-charger-current = <500000>;
		ac-charger-current = <1800000>;
		ac-charger-input-current = <2000000>;
		non-std-ac-charger-current = <1500000>;
		charging-host-charger-current = <1500000>;
		ta-ac-charger-current = <1500000>;
		pd-charger-current = <1500000>;
		/* battery temperature protection */
		temp-t4-threshold = <60>;
		temp-t3-threshold = <45>;
		pre-charger-current = <500000>;
		fast-charge-voltage = <3100>;
		shutdown-voltage = <3200>;
		boot-battery-voltage = <3200000>;
};

&pd_cp_manager {
		compatible = "pd_cp_manager";
		fv = <4492>;
		fv_ffc = <4562>;
		max_fcc = <17600>;
		max_vbus = <20000>;
		max_ibus = <4400>;
		fcc_low_hyst = <150>;
		fcc_high_hyst = <10>;
		low_tbat = <100>;
		high_tbat = <480>;
		high_vbat = <4400>;
		high_soc = <95>;
		low_fcc = <2000>;
		cv_vbat = <4480>;
		cv_vbat_ffc = <4510>;
		cv_ibat = <1200>;
		min_pdo_vbus = <8000>;
		max_pdo_vbus = <21000>;
		mt6375_control_gpio = <&pio 93 0x0>;
		support_4_1_mode;
		support_pmic_parachg;
		switch1_1_enter = <2500>;
		switch1_1_exit = <3700>;
		switch2_1_enter = <4200>;
		switch2_1_exit = <6500>;
		pdm_ibus_gap = <600>;
		pdm_bypass_ibus_gap = <2600>;
		adapter_power = <100>;
		fv_hyst = <9>;
};

&mtk_gauge {
	DISABLE_MTKBATTERY = <(1)>;
	FIXED_BATTERY_TEMPERATURE = <25>;
	#include "dali_mt6991_battery_table.dtsi"
};

/* charger end */

&mt6363_vbuck5 {
  regulator-always-on;
};

&mt6363_vbuck6 {
  regulator-always-on;
};

&mt6363_vsram_digrf {
  regulator-always-on;
};

&mt6363_vcn15 {
  regulator-always-on;
};

&mt6363_vrf12 {
  regulator-always-on;
};

&tboard_thermistor1 {
	compatible = "mediatek,mt6685-tia-ntc";
	#thermal-sensor-cells = <0>;
	reg = <0 0x1c01d128 0 0x4>; /* TIA DATA T0 */
	temperature-lookup-table =
			<(-40000) 4397119>,
			<(-39000) 4092874>,
			<(-38000) 3811717>,
			<(-37000) 3551749>,
			<(-36000) 3311236>,
			<(-35000) 3088599>,
			<(-34000) 2882396>,
			<(-33000) 2691310>,
			<(-32000) 2514137>,
			<(-31000) 2349778>,
			<(-30000) 2197225>,
			<(-29000) 2055558>,
			<(-28000) 1923932>,
			<(-27000) 1801573>,
			<(-26000) 1687773>,
			<(-25000) 1581881>,
			<(-24000) 1483100>,
			<(-23000) 1391113>,
			<(-22000) 1305413>,
			<(-21000) 1225531>,
			<(-20000) 1151037>,
			<(-19000) 1081535>,
			<(-18000) 1016661>,
			<(-17000) 956080>,
			<(-16000) 899481>,
			<(-15000) 846579>,
			<(-14000) 797111>,
			<(-13000) 750834>,
			<(-12000) 707524>,
			<(-11000) 666972>,
			<(-10000) 628988>,
			<(-9000) 593342>,
			<(-8000) 559931>,
			<(-7000) 528602>,
			<(-6000) 499212>,
			<(-5000) 471632>,
			<(-4000) 445772>,
			<(-3000) 421480>,
			<(-2000) 398652>,
			<(-1000) 377193>,
			<0 357012>,
			<1000 338006>,
			<2000 320122>,
			<3000 303287>,
			<4000 287434>,
			<5000 272500>,
			<6000 258426>,
			<7000 245160>,
			<8000 232649>,
			<9000 220847>,
			<10000 209710>,
			<11000 199196>,
			<12000 189268>,
			<13000 179890>,
			<14000 171027>,
			<15000 162651>,
			<16000 154726>,
			<17000 147232>,
			<18000 140142>,
			<19000 133432>,
			<20000 127080>,
			<21000 121066>,
			<22000 115368>,
			<23000 109970>,
			<24000 104852>,
			<25000 100000>,
			<26000 95398>,
			<27000 91032>,
			<28000 86889>,
			<29000 82956>,
			<30000 79222>,
			<31000 75675>,
			<32000 72306>,
			<33000 69104>,
			<34000 66061>,
			<35000 63167>,
			<36000 60415>,
			<37000 57797>,
			<38000 55306>,
			<39000 52934>,
			<40000 50677>,
			<41000 48528>,
			<42000 46482>,
			<43000 44533>,
			<44000 42675>,
			<45000 40904>,
			<46000 39213>,
			<47000 37601>,
			<48000 36063>,
			<49000 34595>,
			<50000 33195>,
			<51000 31859>,
			<52000 30584>,
			<53000 29366>,
			<54000 28203>,
			<55000 27091>,
			<56000 26028>,
			<57000 25013>,
			<58000 24042>,
			<59000 23113>,
			<60000 22224>,
			<61000 21374>,
			<62000 20560>,
			<63000 19782>,
			<64000 19036>,
			<65000 18322>,
			<66000 17640>,
			<67000 16986>,
			<68000 16360>,
			<69000 15759>,
			<70000 15184>,
			<71000 14631>,
			<72000 14100>,
			<73000 13591>,
			<74000 13103>,
			<75000 12635>,
			<76000 12187>,
			<77000 11756>,
			<78000 11343>,
			<79000 10946>,
			<80000 10565>,
			<81000 10199>,
			<82000 9847>,
			<83000 9509>,
			<84000 9184>,
			<85000 8872>,
			<86000 8572>,
			<87000 8283>,
			<88000 8005>,
			<89000 7738>,
			<90000 7481>,
			<91000 7234>,
			<92000 6997>,
			<93000 6769>,
			<94000 6548>,
			<95000 6337>,
			<96000 6132>,
			<97000 5934>,
			<98000 5744>,
			<99000 5561>,
			<100000 5384>,
			<101000 5214>,
			<102000 5051>,
			<103000 4893>,
			<104000 4741>,
			<105000 4594>,
			<106000 4453>,
			<107000 4316>,
			<108000 4184>,
			<109000 4057>,
			<110000 3934>,
			<111000 3816>,
			<112000 3701>,
			<113000 3591>,
			<114000 3484>,
			<115000 3380>,
			<116000 3281>,
			<117000 3185>,
			<118000 3093>,
			<119000 3003>,
			<120000 2916>,
			<121000 2832>,
			<122000 2751>,
			<123000 2672>,
			<124000 2596>,
			<125000 2522>;
};

&tboard_thermistor2 {
	compatible = "mediatek,mt6685-tia-ntc";
	#thermal-sensor-cells = <0>;
	reg = <0 0x1c01d12c 0 0x4>; /* TIA DATA T1 */
	temperature-lookup-table =
			<(-40000) 4397119>,
			<(-39000) 4092874>,
			<(-38000) 3811717>,
			<(-37000) 3551749>,
			<(-36000) 3311236>,
			<(-35000) 3088599>,
			<(-34000) 2882396>,
			<(-33000) 2691310>,
			<(-32000) 2514137>,
			<(-31000) 2349778>,
			<(-30000) 2197225>,
			<(-29000) 2055558>,
			<(-28000) 1923932>,
			<(-27000) 1801573>,
			<(-26000) 1687773>,
			<(-25000) 1581881>,
			<(-24000) 1483100>,
			<(-23000) 1391113>,
			<(-22000) 1305413>,
			<(-21000) 1225531>,
			<(-20000) 1151037>,
			<(-19000) 1081535>,
			<(-18000) 1016661>,
			<(-17000) 956080>,
			<(-16000) 899481>,
			<(-15000) 846579>,
			<(-14000) 797111>,
			<(-13000) 750834>,
			<(-12000) 707524>,
			<(-11000) 666972>,
			<(-10000) 628988>,
			<(-9000) 593342>,
			<(-8000) 559931>,
			<(-7000) 528602>,
			<(-6000) 499212>,
			<(-5000) 471632>,
			<(-4000) 445772>,
			<(-3000) 421480>,
			<(-2000) 398652>,
			<(-1000) 377193>,
			<0 357012>,
			<1000 338006>,
			<2000 320122>,
			<3000 303287>,
			<4000 287434>,
			<5000 272500>,
			<6000 258426>,
			<7000 245160>,
			<8000 232649>,
			<9000 220847>,
			<10000 209710>,
			<11000 199196>,
			<12000 189268>,
			<13000 179890>,
			<14000 171027>,
			<15000 162651>,
			<16000 154726>,
			<17000 147232>,
			<18000 140142>,
			<19000 133432>,
			<20000 127080>,
			<21000 121066>,
			<22000 115368>,
			<23000 109970>,
			<24000 104852>,
			<25000 100000>,
			<26000 95398>,
			<27000 91032>,
			<28000 86889>,
			<29000 82956>,
			<30000 79222>,
			<31000 75675>,
			<32000 72306>,
			<33000 69104>,
			<34000 66061>,
			<35000 63167>,
			<36000 60415>,
			<37000 57797>,
			<38000 55306>,
			<39000 52934>,
			<40000 50677>,
			<41000 48528>,
			<42000 46482>,
			<43000 44533>,
			<44000 42675>,
			<45000 40904>,
			<46000 39213>,
			<47000 37601>,
			<48000 36063>,
			<49000 34595>,
			<50000 33195>,
			<51000 31859>,
			<52000 30584>,
			<53000 29366>,
			<54000 28203>,
			<55000 27091>,
			<56000 26028>,
			<57000 25013>,
			<58000 24042>,
			<59000 23113>,
			<60000 22224>,
			<61000 21374>,
			<62000 20560>,
			<63000 19782>,
			<64000 19036>,
			<65000 18322>,
			<66000 17640>,
			<67000 16986>,
			<68000 16360>,
			<69000 15759>,
			<70000 15184>,
			<71000 14631>,
			<72000 14100>,
			<73000 13591>,
			<74000 13103>,
			<75000 12635>,
			<76000 12187>,
			<77000 11756>,
			<78000 11343>,
			<79000 10946>,
			<80000 10565>,
			<81000 10199>,
			<82000 9847>,
			<83000 9509>,
			<84000 9184>,
			<85000 8872>,
			<86000 8572>,
			<87000 8283>,
			<88000 8005>,
			<89000 7738>,
			<90000 7481>,
			<91000 7234>,
			<92000 6997>,
			<93000 6769>,
			<94000 6548>,
			<95000 6337>,
			<96000 6132>,
			<97000 5934>,
			<98000 5744>,
			<99000 5561>,
			<100000 5384>,
			<101000 5214>,
			<102000 5051>,
			<103000 4893>,
			<104000 4741>,
			<105000 4594>,
			<106000 4453>,
			<107000 4316>,
			<108000 4184>,
			<109000 4057>,
			<110000 3934>,
			<111000 3816>,
			<112000 3701>,
			<113000 3591>,
			<114000 3484>,
			<115000 3380>,
			<116000 3281>,
			<117000 3185>,
			<118000 3093>,
			<119000 3003>,
			<120000 2916>,
			<121000 2832>,
			<122000 2751>,
			<123000 2672>,
			<124000 2596>,
			<125000 2522>;
};

&tboard_thermistor3 {
	compatible = "mediatek,mt6685-tia-ntc";
	#thermal-sensor-cells = <0>;
	reg = <0 0x1c01d130 0 0x4>; /* TIA DATA T2 */
	temperature-lookup-table =
			<(-40000) 4397119>,
			<(-39000) 4092874>,
			<(-38000) 3811717>,
			<(-37000) 3551749>,
			<(-36000) 3311236>,
			<(-35000) 3088599>,
			<(-34000) 2882396>,
			<(-33000) 2691310>,
			<(-32000) 2514137>,
			<(-31000) 2349778>,
			<(-30000) 2197225>,
			<(-29000) 2055558>,
			<(-28000) 1923932>,
			<(-27000) 1801573>,
			<(-26000) 1687773>,
			<(-25000) 1581881>,
			<(-24000) 1483100>,
			<(-23000) 1391113>,
			<(-22000) 1305413>,
			<(-21000) 1225531>,
			<(-20000) 1151037>,
			<(-19000) 1081535>,
			<(-18000) 1016661>,
			<(-17000) 956080>,
			<(-16000) 899481>,
			<(-15000) 846579>,
			<(-14000) 797111>,
			<(-13000) 750834>,
			<(-12000) 707524>,
			<(-11000) 666972>,
			<(-10000) 628988>,
			<(-9000) 593342>,
			<(-8000) 559931>,
			<(-7000) 528602>,
			<(-6000) 499212>,
			<(-5000) 471632>,
			<(-4000) 445772>,
			<(-3000) 421480>,
			<(-2000) 398652>,
			<(-1000) 377193>,
			<0 357012>,
			<1000 338006>,
			<2000 320122>,
			<3000 303287>,
			<4000 287434>,
			<5000 272500>,
			<6000 258426>,
			<7000 245160>,
			<8000 232649>,
			<9000 220847>,
			<10000 209710>,
			<11000 199196>,
			<12000 189268>,
			<13000 179890>,
			<14000 171027>,
			<15000 162651>,
			<16000 154726>,
			<17000 147232>,
			<18000 140142>,
			<19000 133432>,
			<20000 127080>,
			<21000 121066>,
			<22000 115368>,
			<23000 109970>,
			<24000 104852>,
			<25000 100000>,
			<26000 95398>,
			<27000 91032>,
			<28000 86889>,
			<29000 82956>,
			<30000 79222>,
			<31000 75675>,
			<32000 72306>,
			<33000 69104>,
			<34000 66061>,
			<35000 63167>,
			<36000 60415>,
			<37000 57797>,
			<38000 55306>,
			<39000 52934>,
			<40000 50677>,
			<41000 48528>,
			<42000 46482>,
			<43000 44533>,
			<44000 42675>,
			<45000 40904>,
			<46000 39213>,
			<47000 37601>,
			<48000 36063>,
			<49000 34595>,
			<50000 33195>,
			<51000 31859>,
			<52000 30584>,
			<53000 29366>,
			<54000 28203>,
			<55000 27091>,
			<56000 26028>,
			<57000 25013>,
			<58000 24042>,
			<59000 23113>,
			<60000 22224>,
			<61000 21374>,
			<62000 20560>,
			<63000 19782>,
			<64000 19036>,
			<65000 18322>,
			<66000 17640>,
			<67000 16986>,
			<68000 16360>,
			<69000 15759>,
			<70000 15184>,
			<71000 14631>,
			<72000 14100>,
			<73000 13591>,
			<74000 13103>,
			<75000 12635>,
			<76000 12187>,
			<77000 11756>,
			<78000 11343>,
			<79000 10946>,
			<80000 10565>,
			<81000 10199>,
			<82000 9847>,
			<83000 9509>,
			<84000 9184>,
			<85000 8872>,
			<86000 8572>,
			<87000 8283>,
			<88000 8005>,
			<89000 7738>,
			<90000 7481>,
			<91000 7234>,
			<92000 6997>,
			<93000 6769>,
			<94000 6548>,
			<95000 6337>,
			<96000 6132>,
			<97000 5934>,
			<98000 5744>,
			<99000 5561>,
			<100000 5384>,
			<101000 5214>,
			<102000 5051>,
			<103000 4893>,
			<104000 4741>,
			<105000 4594>,
			<106000 4453>,
			<107000 4316>,
			<108000 4184>,
			<109000 4057>,
			<110000 3934>,
			<111000 3816>,
			<112000 3701>,
			<113000 3591>,
			<114000 3484>,
			<115000 3380>,
			<116000 3281>,
			<117000 3185>,
			<118000 3093>,
			<119000 3003>,
			<120000 2916>,
			<121000 2832>,
			<122000 2751>,
			<123000 2672>,
			<124000 2596>,
			<125000 2522>;
};

&tboard_thermistor4 {
	compatible = "generic-adc-thermal";
	#thermal-sensor-cells = <0>;
	io-channels = <&mt6373_adc AUXADC_VIN1>;
	io-channel-names = "sensor-channel";
	temperature-lookup-table =
			<(-40000) 1799>,
			<(-39000) 1796>,
			<(-38000) 1792>,
			<(-37000) 1789>,
			<(-36000) 1786>,
			<(-35000) 1782>,
			<(-34000) 1778>,
			<(-33000) 1774>,
			<(-32000) 1769>,
			<(-31000) 1764>,
			<(-30000) 1759>,
			<(-29000) 1754>,
			<(-28000) 1749>,
			<(-27000) 1743>,
			<(-26000) 1737>,
			<(-25000) 1730>,
			<(-24000) 1723>,
			<(-23000) 1716>,
			<(-22000) 1709>,
			<(-21000) 1701>,
			<(-20000) 1692>,
			<(-19000) 1684>,
			<(-18000) 1675>,
			<(-17000) 1665>,
			<(-16000) 1655>,
			<(-15000) 1645>,
			<(-14000) 1634>,
			<(-13000) 1623>,
			<(-12000) 1612>,
			<(-11000) 1600>,
			<(-10000) 1587>,
			<(-9000) 1574>,
			<(-8000) 1561>,
			<(-7000) 1547>,
			<(-6000) 1532>,
			<(-5000) 1518>,
			<(-4000) 1502>,
			<(-3000) 1487>,
			<(-2000) 1471>,
			<(-1000) 1454>,
			<0 1437>,
			<1000 1419>,
			<2000 1402>,
			<3000 1383>,
			<4000 1365>,
			<5000 1346>,
			<6000 1326>,
			<7000 1306>,
			<8000 1286>,
			<9000 1266>,
			<10000 1245>,
			<11000 1225>,
			<12000 1203>,
			<13000 1182>,
			<14000 1161>,
			<15000 1139>,
			<16000 1117>,
			<17000 1095>,
			<18000 1073>,
			<19000 1051>,
			<20000 1029>,
			<21000 1007>,
			<22000 985>,
			<23000 963>,
			<24000 941>,
			<25000 920>,
			<26000 898>,
			<27000 876>,
			<28000 855>,
			<29000 834>,
			<30000 813>,
			<31000 792>,
			<32000 772>,
			<33000 751>,
			<34000 731>,
			<35000 712>,
			<36000 692>,
			<37000 673>,
			<38000 655>,
			<39000 636>,
			<40000 618>,
			<41000 601>,
			<42000 583>,
			<43000 566>,
			<44000 550>,
			<45000 534>,
			<46000 518>,
			<47000 502>,
			<48000 487>,
			<49000 472>,
			<50000 458>,
			<51000 444>,
			<52000 430>,
			<53000 417>,
			<54000 404>,
			<55000 392>,
			<56000 380>,
			<57000 368>,
			<58000 356>,
			<59000 345>,
			<60000 334>,
			<61000 324>,
			<62000 313>,
			<63000 303>,
			<64000 294>,
			<65000 284>,
			<66000 275>,
			<67000 267>,
			<68000 258>,
			<69000 250>,
			<70000 242>,
			<71000 234>,
			<72000 227>,
			<73000 220>,
			<74000 213>,
			<75000 206>,
			<76000 199>,
			<77000 193>,
			<78000 187>,
			<79000 181>,
			<80000 175>,
			<81000 170>,
			<82000 164>,
			<83000 159>,
			<84000 154>,
			<85000 149>,
			<86000 145>,
			<87000 140>,
			<88000 136>,
			<89000 132>,
			<90000 128>,
			<91000 124>,
			<92000 120>,
			<93000 116>,
			<94000 113>,
			<95000 109>,
			<96000 106>,
			<97000 103>,
			<98000 99>,
			<99000 96>,
			<100000 94>,
			<101000 91>,
			<102000 88>,
			<103000 85>,
			<104000 83>,
			<105000 80>,
			<106000 78>,
			<107000 76>,
			<108000 73>,
			<109000 71>,
			<110000 69>,
			<111000 67>,
			<112000 65>,
			<113000 63>,
			<114000 61>,
			<115000 60>,
			<116000 58>,
			<117000 56>,
			<118000 55>,
			<119000 53>,
			<120000 52>,
			<121000 50>,
			<122000 49>,
			<123000 47>,
			<124000 46>,
			<125000 45>;
};

&tboard_thermistor5 {
	compatible = "generic-adc-thermal";
	#thermal-sensor-cells = <0>;
	io-channels = <&mt6373_adc AUXADC_VIN2>;
	io-channel-names = "sensor-channel";
	temperature-lookup-table =
			<(-40000) 1799>,
			<(-39000) 1796>,
			<(-38000) 1792>,
			<(-37000) 1789>,
			<(-36000) 1786>,
			<(-35000) 1782>,
			<(-34000) 1778>,
			<(-33000) 1774>,
			<(-32000) 1769>,
			<(-31000) 1764>,
			<(-30000) 1759>,
			<(-29000) 1754>,
			<(-28000) 1749>,
			<(-27000) 1743>,
			<(-26000) 1737>,
			<(-25000) 1730>,
			<(-24000) 1723>,
			<(-23000) 1716>,
			<(-22000) 1709>,
			<(-21000) 1701>,
			<(-20000) 1692>,
			<(-19000) 1684>,
			<(-18000) 1675>,
			<(-17000) 1665>,
			<(-16000) 1655>,
			<(-15000) 1645>,
			<(-14000) 1634>,
			<(-13000) 1623>,
			<(-12000) 1612>,
			<(-11000) 1600>,
			<(-10000) 1587>,
			<(-9000) 1574>,
			<(-8000) 1561>,
			<(-7000) 1547>,
			<(-6000) 1532>,
			<(-5000) 1518>,
			<(-4000) 1502>,
			<(-3000) 1487>,
			<(-2000) 1471>,
			<(-1000) 1454>,
			<0 1437>,
			<1000 1419>,
			<2000 1402>,
			<3000 1383>,
			<4000 1365>,
			<5000 1346>,
			<6000 1326>,
			<7000 1306>,
			<8000 1286>,
			<9000 1266>,
			<10000 1245>,
			<11000 1225>,
			<12000 1203>,
			<13000 1182>,
			<14000 1161>,
			<15000 1139>,
			<16000 1117>,
			<17000 1095>,
			<18000 1073>,
			<19000 1051>,
			<20000 1029>,
			<21000 1007>,
			<22000 985>,
			<23000 963>,
			<24000 941>,
			<25000 920>,
			<26000 898>,
			<27000 876>,
			<28000 855>,
			<29000 834>,
			<30000 813>,
			<31000 792>,
			<32000 772>,
			<33000 751>,
			<34000 731>,
			<35000 712>,
			<36000 692>,
			<37000 673>,
			<38000 655>,
			<39000 636>,
			<40000 618>,
			<41000 601>,
			<42000 583>,
			<43000 566>,
			<44000 550>,
			<45000 534>,
			<46000 518>,
			<47000 502>,
			<48000 487>,
			<49000 472>,
			<50000 458>,
			<51000 444>,
			<52000 430>,
			<53000 417>,
			<54000 404>,
			<55000 392>,
			<56000 380>,
			<57000 368>,
			<58000 356>,
			<59000 345>,
			<60000 334>,
			<61000 324>,
			<62000 313>,
			<63000 303>,
			<64000 294>,
			<65000 284>,
			<66000 275>,
			<67000 267>,
			<68000 258>,
			<69000 250>,
			<70000 242>,
			<71000 234>,
			<72000 227>,
			<73000 220>,
			<74000 213>,
			<75000 206>,
			<76000 199>,
			<77000 193>,
			<78000 187>,
			<79000 181>,
			<80000 175>,
			<81000 170>,
			<82000 164>,
			<83000 159>,
			<84000 154>,
			<85000 149>,
			<86000 145>,
			<87000 140>,
			<88000 136>,
			<89000 132>,
			<90000 128>,
			<91000 124>,
			<92000 120>,
			<93000 116>,
			<94000 113>,
			<95000 109>,
			<96000 106>,
			<97000 103>,
			<98000 99>,
			<99000 96>,
			<100000 94>,
			<101000 91>,
			<102000 88>,
			<103000 85>,
			<104000 83>,
			<105000 80>,
			<106000 78>,
			<107000 76>,
			<108000 73>,
			<109000 71>,
			<110000 69>,
			<111000 67>,
			<112000 65>,
			<113000 63>,
			<114000 61>,
			<115000 60>,
			<116000 58>,
			<117000 56>,
			<118000 55>,
			<119000 53>,
			<120000 52>,
			<121000 50>,
			<122000 49>,
			<123000 47>,
			<124000 46>,
			<125000 45>;
};

&tboard_thermistor6 {
	compatible = "generic-adc-thermal";
	#thermal-sensor-cells = <0>;
	io-channels = <&mt6373_adc AUXADC_VIN4>;
	io-channel-names = "sensor-channel";
	temperature-lookup-table =
			<(-40000) 1799>,
			<(-39000) 1796>,
			<(-38000) 1792>,
			<(-37000) 1789>,
			<(-36000) 1786>,
			<(-35000) 1782>,
			<(-34000) 1778>,
			<(-33000) 1774>,
			<(-32000) 1769>,
			<(-31000) 1764>,
			<(-30000) 1759>,
			<(-29000) 1754>,
			<(-28000) 1749>,
			<(-27000) 1743>,
			<(-26000) 1737>,
			<(-25000) 1730>,
			<(-24000) 1723>,
			<(-23000) 1716>,
			<(-22000) 1709>,
			<(-21000) 1701>,
			<(-20000) 1692>,
			<(-19000) 1684>,
			<(-18000) 1675>,
			<(-17000) 1665>,
			<(-16000) 1655>,
			<(-15000) 1645>,
			<(-14000) 1634>,
			<(-13000) 1623>,
			<(-12000) 1612>,
			<(-11000) 1600>,
			<(-10000) 1587>,
			<(-9000) 1574>,
			<(-8000) 1561>,
			<(-7000) 1547>,
			<(-6000) 1532>,
			<(-5000) 1518>,
			<(-4000) 1502>,
			<(-3000) 1487>,
			<(-2000) 1471>,
			<(-1000) 1454>,
			<0 1437>,
			<1000 1419>,
			<2000 1402>,
			<3000 1383>,
			<4000 1365>,
			<5000 1346>,
			<6000 1326>,
			<7000 1306>,
			<8000 1286>,
			<9000 1266>,
			<10000 1245>,
			<11000 1225>,
			<12000 1203>,
			<13000 1182>,
			<14000 1161>,
			<15000 1139>,
			<16000 1117>,
			<17000 1095>,
			<18000 1073>,
			<19000 1051>,
			<20000 1029>,
			<21000 1007>,
			<22000 985>,
			<23000 963>,
			<24000 941>,
			<25000 920>,
			<26000 898>,
			<27000 876>,
			<28000 855>,
			<29000 834>,
			<30000 813>,
			<31000 792>,
			<32000 772>,
			<33000 751>,
			<34000 731>,
			<35000 712>,
			<36000 692>,
			<37000 673>,
			<38000 655>,
			<39000 636>,
			<40000 618>,
			<41000 601>,
			<42000 583>,
			<43000 566>,
			<44000 550>,
			<45000 534>,
			<46000 518>,
			<47000 502>,
			<48000 487>,
			<49000 472>,
			<50000 458>,
			<51000 444>,
			<52000 430>,
			<53000 417>,
			<54000 404>,
			<55000 392>,
			<56000 380>,
			<57000 368>,
			<58000 356>,
			<59000 345>,
			<60000 334>,
			<61000 324>,
			<62000 313>,
			<63000 303>,
			<64000 294>,
			<65000 284>,
			<66000 275>,
			<67000 267>,
			<68000 258>,
			<69000 250>,
			<70000 242>,
			<71000 234>,
			<72000 227>,
			<73000 220>,
			<74000 213>,
			<75000 206>,
			<76000 199>,
			<77000 193>,
			<78000 187>,
			<79000 181>,
			<80000 175>,
			<81000 170>,
			<82000 164>,
			<83000 159>,
			<84000 154>,
			<85000 149>,
			<86000 145>,
			<87000 140>,
			<88000 136>,
			<89000 132>,
			<90000 128>,
			<91000 124>,
			<92000 120>,
			<93000 116>,
			<94000 113>,
			<95000 109>,
			<96000 106>,
			<97000 103>,
			<98000 99>,
			<99000 96>,
			<100000 94>,
			<101000 91>,
			<102000 88>,
			<103000 85>,
			<104000 83>,
			<105000 80>,
			<106000 78>,
			<107000 76>,
			<108000 73>,
			<109000 71>,
			<110000 69>,
			<111000 67>,
			<112000 65>,
			<113000 63>,
			<114000 61>,
			<115000 60>,
			<116000 58>,
			<117000 56>,
			<118000 55>,
			<119000 53>,
			<120000 52>,
			<121000 50>,
			<122000 49>,
			<123000 47>,
			<124000 46>,
			<125000 45>;
};

&tboard_thermistor7 {
	compatible = "generic-adc-thermal";
	#thermal-sensor-cells = <0>;
	io-channels = <&mt6373_adc AUXADC_VIN5>;
	io-channel-names = "sensor-channel";
	temperature-lookup-table =
			<(-40000) 1799>,
			<(-39000) 1796>,
			<(-38000) 1792>,
			<(-37000) 1789>,
			<(-36000) 1786>,
			<(-35000) 1782>,
			<(-34000) 1778>,
			<(-33000) 1774>,
			<(-32000) 1769>,
			<(-31000) 1764>,
			<(-30000) 1759>,
			<(-29000) 1754>,
			<(-28000) 1749>,
			<(-27000) 1743>,
			<(-26000) 1737>,
			<(-25000) 1730>,
			<(-24000) 1723>,
			<(-23000) 1716>,
			<(-22000) 1709>,
			<(-21000) 1701>,
			<(-20000) 1692>,
			<(-19000) 1684>,
			<(-18000) 1675>,
			<(-17000) 1665>,
			<(-16000) 1655>,
			<(-15000) 1645>,
			<(-14000) 1634>,
			<(-13000) 1623>,
			<(-12000) 1612>,
			<(-11000) 1600>,
			<(-10000) 1587>,
			<(-9000) 1574>,
			<(-8000) 1561>,
			<(-7000) 1547>,
			<(-6000) 1532>,
			<(-5000) 1518>,
			<(-4000) 1502>,
			<(-3000) 1487>,
			<(-2000) 1471>,
			<(-1000) 1454>,
			<0 1437>,
			<1000 1419>,
			<2000 1402>,
			<3000 1383>,
			<4000 1365>,
			<5000 1346>,
			<6000 1326>,
			<7000 1306>,
			<8000 1286>,
			<9000 1266>,
			<10000 1245>,
			<11000 1225>,
			<12000 1203>,
			<13000 1182>,
			<14000 1161>,
			<15000 1139>,
			<16000 1117>,
			<17000 1095>,
			<18000 1073>,
			<19000 1051>,
			<20000 1029>,
			<21000 1007>,
			<22000 985>,
			<23000 963>,
			<24000 941>,
			<25000 920>,
			<26000 898>,
			<27000 876>,
			<28000 855>,
			<29000 834>,
			<30000 813>,
			<31000 792>,
			<32000 772>,
			<33000 751>,
			<34000 731>,
			<35000 712>,
			<36000 692>,
			<37000 673>,
			<38000 655>,
			<39000 636>,
			<40000 618>,
			<41000 601>,
			<42000 583>,
			<43000 566>,
			<44000 550>,
			<45000 534>,
			<46000 518>,
			<47000 502>,
			<48000 487>,
			<49000 472>,
			<50000 458>,
			<51000 444>,
			<52000 430>,
			<53000 417>,
			<54000 404>,
			<55000 392>,
			<56000 380>,
			<57000 368>,
			<58000 356>,
			<59000 345>,
			<60000 334>,
			<61000 324>,
			<62000 313>,
			<63000 303>,
			<64000 294>,
			<65000 284>,
			<66000 275>,
			<67000 267>,
			<68000 258>,
			<69000 250>,
			<70000 242>,
			<71000 234>,
			<72000 227>,
			<73000 220>,
			<74000 213>,
			<75000 206>,
			<76000 199>,
			<77000 193>,
			<78000 187>,
			<79000 181>,
			<80000 175>,
			<81000 170>,
			<82000 164>,
			<83000 159>,
			<84000 154>,
			<85000 149>,
			<86000 145>,
			<87000 140>,
			<88000 136>,
			<89000 132>,
			<90000 128>,
			<91000 124>,
			<92000 120>,
			<93000 116>,
			<94000 113>,
			<95000 109>,
			<96000 106>,
			<97000 103>,
			<98000 99>,
			<99000 96>,
			<100000 94>,
			<101000 91>,
			<102000 88>,
			<103000 85>,
			<104000 83>,
			<105000 80>,
			<106000 78>,
			<107000 76>,
			<108000 73>,
			<109000 71>,
			<110000 69>,
			<111000 67>,
			<112000 65>,
			<113000 63>,
			<114000 61>,
			<115000 60>,
			<116000 58>,
			<117000 56>,
			<118000 55>,
			<119000 53>,
			<120000 52>,
			<121000 50>,
			<122000 49>,
			<123000 47>,
			<124000 46>,
			<125000 45>;
};

&tboard_thermistor8 {
	compatible = "generic-adc-thermal";
	#thermal-sensor-cells = <0>;
	io-channels = <&pmic_adc AUXADC_VIN3>;
	io-channel-names = "sensor-channel";
	temperature-lookup-table =
		<(-40000) 1799>,
		<(-39000) 1797>,
		<(-38000) 1794>,
		<(-37000) 1790>,
		<(-36000) 1787>,
		<(-35000) 1783>,
		<(-34000) 1779>,
		<(-33000) 1775>,
		<(-32000) 1771>,
		<(-31000) 1766>,
		<(-30000) 1761>,
		<(-29000) 1756>,
		<(-28000) 1751>,
		<(-27000) 1745>,
		<(-26000) 1739>,
		<(-25000) 1733>,
		<(-24000) 1726>,
		<(-23000) 1719>,
		<(-22000) 1712>,
		<(-21000) 1705>,
		<(-20000) 1696>,
		<(-19000) 1688>,
		<(-18000) 1678>,
		<(-17000) 1669>,
		<(-16000) 1659>,
		<(-15000) 1649>,
		<(-14000) 1640>,
		<(-13000) 1628>,
		<(-12000) 1617>,
		<(-11000) 1605>,
		<(-10000) 1592>,
		<(-9000) 1580>,
		<(-8000) 1567>,
		<(-7000) 1554>,
		<(-6000) 1539>,
		<(-5000) 1526>,
		<(-4000) 1509>,
		<(-3000) 1493>,
		<(-2000) 1477>,
		<(-1000) 1460>,
		<0 1445>,
		<1000 1427>,
		<2000 1409>,
		<3000 1391>,
		<4000 1373>,
		<5000 1354>,
		<6000 1335>,
		<7000 1314>,
		<8000 1295>,
		<9000 1276>,
		<10000 1255>,
		<11000 1233>,
		<12000 1212>,
		<13000 1190>,
		<14000 1169>,
		<15000 1147>,
		<16000 1125>,
		<17000 1104>,
		<18000 1082>,
		<19000 1059>,
		<20000 1039>,
		<21000 1016>,
		<22000 993>,
		<23000 971>,
		<24000 942>,
		<25000 920>,
		<26000 899>,
		<27000 878>,
		<28000 856>,
		<29000 835>,
		<30000 814>,
		<31000 794>,
		<32000 773>,
		<33000 753>,
		<34000 733>,
		<35000 714>,
		<36000 694>,
		<37000 676>,
		<38000 656>,
		<39000 638>,
		<40000 620>,
		<41000 602>,
		<42000 587>,
		<43000 570>,
		<44000 551>,
		<45000 534>,
		<46000 518>,
		<47000 503>,
		<48000 488>,
		<49000 473>,
		<50000 459>,
		<51000 444>,
		<52000 431>,
		<53000 417>,
		<54000 404>,
		<55000 392>,
		<56000 379>,
		<57000 368>,
		<58000 356>,
		<59000 345>,
		<60000 334>,
		<61000 323>,
		<62000 313>,
		<63000 303>,
		<64000 293>,
		<65000 284>,
		<66000 275>,
		<67000 266>,
		<68000 258>,
		<69000 250>,
		<70000 242>,
		<71000 234>,
		<72000 226>,
		<73000 219>,
		<74000 212>,
		<75000 206>,
		<76000 199>,
		<77000 193>,
		<78000 187>,
		<79000 181>,
		<80000 175>,
		<81000 169>,
		<82000 164>,
		<83000 159>,
		<84000 154>,
		<85000 149>,
		<86000 144>,
		<87000 140>,
		<88000 136>,
		<89000 131>,
		<90000 127>,
		<91000 123>,
		<92000 120>,
		<93000 116>,
		<94000 112>,
		<95000 109>,
		<96000 105>,
		<97000 102>,
		<98000 99>,
		<99000 96>,
		<100000 93>,
		<101000 90>,
		<102000 88>,
		<103000 85>,
		<104000 82>,
		<105000 80>,
		<106000 78>,
		<107000 75>,
		<108000 73>,
		<109000 71>,
		<110000 69>,
		<111000 67>,
		<112000 65>,
		<113000 63>,
		<114000 61>,
		<115000 59>,
		<116000 58>,
		<117000 56>,
		<118000 55>,
		<119000 53>,
		<120000 51>,
		<121000 50>,
		<122000 49>,
		<123000 47>,
		<124000 46>,
		<125000 45>;
};

&tboard_thermistor9 {
	compatible = "generic-adc-thermal";
	#thermal-sensor-cells = <0>;
	io-channels = <&pmic_adc AUXADC_VIN5>;
	io-channel-names = "sensor-channel";
	temperature-lookup-table =
		<(-40000) 1799>,
		<(-39000) 1797>,
		<(-38000) 1794>,
		<(-37000) 1790>,
		<(-36000) 1787>,
		<(-35000) 1783>,
		<(-34000) 1779>,
		<(-33000) 1775>,
		<(-32000) 1771>,
		<(-31000) 1766>,
		<(-30000) 1761>,
		<(-29000) 1756>,
		<(-28000) 1751>,
		<(-27000) 1745>,
		<(-26000) 1739>,
		<(-25000) 1733>,
		<(-24000) 1726>,
		<(-23000) 1719>,
		<(-22000) 1712>,
		<(-21000) 1705>,
		<(-20000) 1696>,
		<(-19000) 1688>,
		<(-18000) 1678>,
		<(-17000) 1669>,
		<(-16000) 1659>,
		<(-15000) 1649>,
		<(-14000) 1640>,
		<(-13000) 1628>,
		<(-12000) 1617>,
		<(-11000) 1605>,
		<(-10000) 1592>,
		<(-9000) 1580>,
		<(-8000) 1567>,
		<(-7000) 1554>,
		<(-6000) 1539>,
		<(-5000) 1526>,
		<(-4000) 1509>,
		<(-3000) 1493>,
		<(-2000) 1477>,
		<(-1000) 1460>,
		<0 1445>,
		<1000 1427>,
		<2000 1409>,
		<3000 1391>,
		<4000 1373>,
		<5000 1354>,
		<6000 1335>,
		<7000 1314>,
		<8000 1295>,
		<9000 1276>,
		<10000 1255>,
		<11000 1233>,
		<12000 1212>,
		<13000 1190>,
		<14000 1169>,
		<15000 1147>,
		<16000 1125>,
		<17000 1104>,
		<18000 1082>,
		<19000 1059>,
		<20000 1039>,
		<21000 1016>,
		<22000 993>,
		<23000 971>,
		<24000 942>,
		<25000 920>,
		<26000 899>,
		<27000 878>,
		<28000 856>,
		<29000 835>,
		<30000 814>,
		<31000 794>,
		<32000 773>,
		<33000 753>,
		<34000 733>,
		<35000 714>,
		<36000 694>,
		<37000 676>,
		<38000 656>,
		<39000 638>,
		<40000 620>,
		<41000 602>,
		<42000 587>,
		<43000 570>,
		<44000 551>,
		<45000 534>,
		<46000 518>,
		<47000 503>,
		<48000 488>,
		<49000 473>,
		<50000 459>,
		<51000 444>,
		<52000 431>,
		<53000 417>,
		<54000 404>,
		<55000 392>,
		<56000 379>,
		<57000 368>,
		<58000 356>,
		<59000 345>,
		<60000 334>,
		<61000 323>,
		<62000 313>,
		<63000 303>,
		<64000 293>,
		<65000 284>,
		<66000 275>,
		<67000 266>,
		<68000 258>,
		<69000 250>,
		<70000 242>,
		<71000 234>,
		<72000 226>,
		<73000 219>,
		<74000 212>,
		<75000 206>,
		<76000 199>,
		<77000 193>,
		<78000 187>,
		<79000 181>,
		<80000 175>,
		<81000 169>,
		<82000 164>,
		<83000 159>,
		<84000 154>,
		<85000 149>,
		<86000 144>,
		<87000 140>,
		<88000 136>,
		<89000 131>,
		<90000 127>,
		<91000 123>,
		<92000 120>,
		<93000 116>,
		<94000 112>,
		<95000 109>,
		<96000 105>,
		<97000 102>,
		<98000 99>,
		<99000 96>,
		<100000 93>,
		<101000 90>,
		<102000 88>,
		<103000 85>,
		<104000 82>,
		<105000 80>,
		<106000 78>,
		<107000 75>,
		<108000 73>,
		<109000 71>,
		<110000 69>,
		<111000 67>,
		<112000 65>,
		<113000 63>,
		<114000 61>,
		<115000 59>,
		<116000 58>,
		<117000 56>,
		<118000 55>,
		<119000 53>,
		<120000 51>,
		<121000 50>,
		<122000 49>,
		<123000 47>,
		<124000 46>,
		<125000 45>;
};

&tboard_thermistor10 {
	compatible = "generic-adc-thermal";
	#thermal-sensor-cells = <0>;
	io-channels = <&pmic_adc AUXADC_VIN6>;
	io-channel-names = "sensor-channel";
	temperature-lookup-table =
		<(-40000) 1799>,
		<(-39000) 1797>,
		<(-38000) 1794>,
		<(-37000) 1790>,
		<(-36000) 1787>,
		<(-35000) 1783>,
		<(-34000) 1779>,
		<(-33000) 1775>,
		<(-32000) 1771>,
		<(-31000) 1766>,
		<(-30000) 1761>,
		<(-29000) 1756>,
		<(-28000) 1751>,
		<(-27000) 1745>,
		<(-26000) 1739>,
		<(-25000) 1733>,
		<(-24000) 1726>,
		<(-23000) 1719>,
		<(-22000) 1712>,
		<(-21000) 1705>,
		<(-20000) 1696>,
		<(-19000) 1688>,
		<(-18000) 1678>,
		<(-17000) 1669>,
		<(-16000) 1659>,
		<(-15000) 1649>,
		<(-14000) 1640>,
		<(-13000) 1628>,
		<(-12000) 1617>,
		<(-11000) 1605>,
		<(-10000) 1592>,
		<(-9000) 1580>,
		<(-8000) 1567>,
		<(-7000) 1554>,
		<(-6000) 1539>,
		<(-5000) 1526>,
		<(-4000) 1509>,
		<(-3000) 1493>,
		<(-2000) 1477>,
		<(-1000) 1460>,
		<0 1445>,
		<1000 1427>,
		<2000 1409>,
		<3000 1391>,
		<4000 1373>,
		<5000 1354>,
		<6000 1335>,
		<7000 1314>,
		<8000 1295>,
		<9000 1276>,
		<10000 1255>,
		<11000 1233>,
		<12000 1212>,
		<13000 1190>,
		<14000 1169>,
		<15000 1147>,
		<16000 1125>,
		<17000 1104>,
		<18000 1082>,
		<19000 1059>,
		<20000 1039>,
		<21000 1016>,
		<22000 993>,
		<23000 971>,
		<24000 942>,
		<25000 920>,
		<26000 899>,
		<27000 878>,
		<28000 856>,
		<29000 835>,
		<30000 814>,
		<31000 794>,
		<32000 773>,
		<33000 753>,
		<34000 733>,
		<35000 714>,
		<36000 694>,
		<37000 676>,
		<38000 656>,
		<39000 638>,
		<40000 620>,
		<41000 602>,
		<42000 587>,
		<43000 570>,
		<44000 551>,
		<45000 534>,
		<46000 518>,
		<47000 503>,
		<48000 488>,
		<49000 473>,
		<50000 459>,
		<51000 444>,
		<52000 431>,
		<53000 417>,
		<54000 404>,
		<55000 392>,
		<56000 379>,
		<57000 368>,
		<58000 356>,
		<59000 345>,
		<60000 334>,
		<61000 323>,
		<62000 313>,
		<63000 303>,
		<64000 293>,
		<65000 284>,
		<66000 275>,
		<67000 266>,
		<68000 258>,
		<69000 250>,
		<70000 242>,
		<71000 234>,
		<72000 226>,
		<73000 219>,
		<74000 212>,
		<75000 206>,
		<76000 199>,
		<77000 193>,
		<78000 187>,
		<79000 181>,
		<80000 175>,
		<81000 169>,
		<82000 164>,
		<83000 159>,
		<84000 154>,
		<85000 149>,
		<86000 144>,
		<87000 140>,
		<88000 136>,
		<89000 131>,
		<90000 127>,
		<91000 123>,
		<92000 120>,
		<93000 116>,
		<94000 112>,
		<95000 109>,
		<96000 105>,
		<97000 102>,
		<98000 99>,
		<99000 96>,
		<100000 93>,
		<101000 90>,
		<102000 88>,
		<103000 85>,
		<104000 82>,
		<105000 80>,
		<106000 78>,
		<107000 75>,
		<108000 73>,
		<109000 71>,
		<110000 69>,
		<111000 67>,
		<112000 65>,
		<113000 63>,
		<114000 61>,
		<115000 59>,
		<116000 58>,
		<117000 56>,
		<118000 55>,
		<119000 53>,
		<120000 51>,
		<121000 50>,
		<122000 49>,
		<123000 47>,
		<124000 46>,
		<125000 45>;
};

&tboard_thermistor11 {
	compatible = "generic-adc-thermal";
	#thermal-sensor-cells = <0>;
	io-channels = <&pmic_adc AUXADC_VIN7>;
	io-channel-names = "sensor-channel";
	temperature-lookup-table =
		<(-40000) 1799>,
		<(-39000) 1797>,
		<(-38000) 1794>,
		<(-37000) 1790>,
		<(-36000) 1787>,
		<(-35000) 1783>,
		<(-34000) 1779>,
		<(-33000) 1775>,
		<(-32000) 1771>,
		<(-31000) 1766>,
		<(-30000) 1761>,
		<(-29000) 1756>,
		<(-28000) 1751>,
		<(-27000) 1745>,
		<(-26000) 1739>,
		<(-25000) 1733>,
		<(-24000) 1726>,
		<(-23000) 1719>,
		<(-22000) 1712>,
		<(-21000) 1705>,
		<(-20000) 1696>,
		<(-19000) 1688>,
		<(-18000) 1678>,
		<(-17000) 1669>,
		<(-16000) 1659>,
		<(-15000) 1649>,
		<(-14000) 1640>,
		<(-13000) 1628>,
		<(-12000) 1617>,
		<(-11000) 1605>,
		<(-10000) 1592>,
		<(-9000) 1580>,
		<(-8000) 1567>,
		<(-7000) 1554>,
		<(-6000) 1539>,
		<(-5000) 1526>,
		<(-4000) 1509>,
		<(-3000) 1493>,
		<(-2000) 1477>,
		<(-1000) 1460>,
		<0 1445>,
		<1000 1427>,
		<2000 1409>,
		<3000 1391>,
		<4000 1373>,
		<5000 1354>,
		<6000 1335>,
		<7000 1314>,
		<8000 1295>,
		<9000 1276>,
		<10000 1255>,
		<11000 1233>,
		<12000 1212>,
		<13000 1190>,
		<14000 1169>,
		<15000 1147>,
		<16000 1125>,
		<17000 1104>,
		<18000 1082>,
		<19000 1059>,
		<20000 1039>,
		<21000 1016>,
		<22000 993>,
		<23000 971>,
		<24000 942>,
		<25000 920>,
		<26000 899>,
		<27000 878>,
		<28000 856>,
		<29000 835>,
		<30000 814>,
		<31000 794>,
		<32000 773>,
		<33000 753>,
		<34000 733>,
		<35000 714>,
		<36000 694>,
		<37000 676>,
		<38000 656>,
		<39000 638>,
		<40000 620>,
		<41000 602>,
		<42000 587>,
		<43000 570>,
		<44000 551>,
		<45000 534>,
		<46000 518>,
		<47000 503>,
		<48000 488>,
		<49000 473>,
		<50000 459>,
		<51000 444>,
		<52000 431>,
		<53000 417>,
		<54000 404>,
		<55000 392>,
		<56000 379>,
		<57000 368>,
		<58000 356>,
		<59000 345>,
		<60000 334>,
		<61000 323>,
		<62000 313>,
		<63000 303>,
		<64000 293>,
		<65000 284>,
		<66000 275>,
		<67000 266>,
		<68000 258>,
		<69000 250>,
		<70000 242>,
		<71000 234>,
		<72000 226>,
		<73000 219>,
		<74000 212>,
		<75000 206>,
		<76000 199>,
		<77000 193>,
		<78000 187>,
		<79000 181>,
		<80000 175>,
		<81000 169>,
		<82000 164>,
		<83000 159>,
		<84000 154>,
		<85000 149>,
		<86000 144>,
		<87000 140>,
		<88000 136>,
		<89000 131>,
		<90000 127>,
		<91000 123>,
		<92000 120>,
		<93000 116>,
		<94000 112>,
		<95000 109>,
		<96000 105>,
		<97000 102>,
		<98000 99>,
		<99000 96>,
		<100000 93>,
		<101000 90>,
		<102000 88>,
		<103000 85>,
		<104000 82>,
		<105000 80>,
		<106000 78>,
		<107000 75>,
		<108000 73>,
		<109000 71>,
		<110000 69>,
		<111000 67>,
		<112000 65>,
		<113000 63>,
		<114000 61>,
		<115000 59>,
		<116000 58>,
		<117000 56>,
		<118000 55>,
		<119000 53>,
		<120000 51>,
		<121000 50>,
		<122000 49>,
		<123000 47>,
		<124000 46>,
		<125000 45>;
};

&thermal_zones {
	quiet_therm: quiet_therm {
		polling-delay = <0>; /* milliseconds */
		polling-delay-passive = <0>; /* milliseconds */
		thermal-sensors = <&tboard_thermistor4>;

		trips {
			quiet_therm_crit: quiet-therm-crit {
				temperature = <119000>;
				hysteresis = <2000>;
				type = "passive";
			};
		};
	};
	charger1_therm: charger1_therm {
		polling-delay = <0>; /* milliseconds */
		polling-delay-passive = <0>; /* milliseconds */
		thermal-sensors = <&tboard_thermistor5>;

		trips {
			charger1_therm_crit: charger1-therm-crit {
				temperature = <119000>;
				hysteresis = <2000>;
				type = "passive";
			};
		};
	};
	wifi_therm: wifi_therm {
		polling-delay = <0>; /* milliseconds */
		polling-delay-passive = <0>; /* milliseconds */
		thermal-sensors = <&tboard_thermistor6>;

		trips {
			wifi_therm_crit: wifi-therm-crit {
				temperature = <119000>;
				hysteresis = <2000>;
				type = "passive";
			};
		};
	};
	flash_therm: flash_therm {
		polling-delay = <0>; /* milliseconds */
		polling-delay-passive = <0>; /* milliseconds */
		thermal-sensors = <&tboard_thermistor7>;

		trips {
			flash_therm_crit: flash-therm-crit {
				temperature = <119000>;
				hysteresis = <2000>;
				type = "passive";
			};
		};
	};
	conn1_therm: conn1_therm {
		polling-delay = <0>; /* milliseconds */
		polling-delay-passive = <0>; /* milliseconds */
		thermal-sensors = <&tboard_thermistor8>;

		trips {
			conn1_therm_crit: conn1-therm-crit {
				temperature = <119000>;
				hysteresis = <2000>;
				type = "passive";
			};
		};
	};
	X7_therm: X7_therm {
		polling-delay = <0>; /* milliseconds */
		polling-delay-passive = <0>; /* milliseconds */
		thermal-sensors = <&tboard_thermistor9>;

		trips {
			X7_therm_crit: X7-therm-crit {
				temperature = <119000>;
				hysteresis = <2000>;
				type = "passive";
			};
		};
	};
	ScreenPmic_therm: ScreenPmic_therm {
		polling-delay = <0>; /* milliseconds */
		polling-delay-passive = <0>; /* milliseconds */
		thermal-sensors = <&tboard_thermistor10>;

		trips {
			ScreenPmic_therm_crit: ScreenPmic-therm-crit {
				temperature = <119000>;
				hysteresis = <2000>;
				type = "passive";
			};
		};
	};
	conn2_therm: conn2_therm {
		polling-delay = <0>; /* milliseconds */
		polling-delay-passive = <0>; /* milliseconds */
		thermal-sensors = <&tboard_thermistor11>;

		trips {
			conn2_therm_crit: conn2-therm-crit {
				temperature = <119000>;
				hysteresis = <2000>;
				type = "passive";
			};
		};
	};
};

&mtee_svp {
	mtee: MTEE {
		compatible = "mediatek,mtk_svp_on_mtee_support";
	};

	svp: SecureVideoPath {
		compatible = "mediatek,mtk_sec_video_path_support";
	};
};

&mtkheap_page_tee {
	status = "ok";
};

&mtkheap_page_svp {
	status = "ok";
};

#include "dali/cust.dtsi"
#include "mediatek/cust_mt6991_nfc_nxp.dtsi"
#include "mediatek/cust_k6991_connfem.dtsi"

#include "mediatek/xiaomi_dali_mt6991_touch.dtsi"
#include "mediatek/xiaomi_dali_mt6991_mitee.dtsi"
#include "mediatek/dali_mt6991_camera_v4l2.dtsi"
#include "mediatek/xiaomi_dali_mt6991_fingerprint.dtsi"

/*End of this file, DO NOT ADD ANYTHING HERE*/

